VERSION ""

NS_ :

BS_:

BU_: Vector__XXX

BO_ 2449527809 SCU1_Alarm: 8 Vector__XXX
SG_ SCU1_af_CellVoltageMax : 0|1@1+ (1,0) [0|1] "" Vector__XXX
SG_ SCU1_af_CellVoltageMin : 1|1@1+ (1,0) [0|1] "" Vector__XXX
SG_ SCU1_af_SysVoltageMax : 2|1@1+ (1,0) [0|1] "" Vector__XXX
SG_ SCU1_af_SysVoltageMin : 3|1@1+ (1,0) [0|1] "" Vector__XXX
SG_ SCU1_af_SysVoltageSum : 4|1@1+ (1,0) [0|1] "" Vector__XXX
SG_ SCU1_af_ModVoltageSum : 5|1@1+ (1,0) [0|1] "" Vector__XXX
SG_ SCU1_af_ModVoltageRefMax : 6|1@1+ (1,0) [0|1] "" Vector__XXX
SG_ SCU1_af_Mod_Voltage_Ref_Min : 7|1@1+ (1,0) [0|1] "" Vector__XXX
SG_ SCU1_af_IsoFaultBattNeg : 8|1@1+ (1,0) [0|1] "" Vector__XXX
SG_ SCU1_af_IsoFaultBattPos : 9|1@1+ (1,0) [0|1] "" Vector__XXX
SG_ SCU1_af_ContactorNegStuck : 10|1@1+ (1,0) [0|1] "" Vector__XXX
SG_ SCU1_af_ContactorPosStuck : 11|1@1+ (1,0) [0|1] "" Vector__XXX
SG_ SCU1_af_LVSupplyMax : 12|1@1+ (1,0) [0|1] "" Vector__XXX
SG_ SCU1_af_LVSupplyMin : 13|1@1+ (1,0) [0|1] "" Vector__XXX
SG_ SCU1_af_TerminalTempMax : 14|1@1+ (1,0) [0|1] "" Vector__XXX
SG_ SCU1_af_TerminalTempMin : 15|1@1+ (1,0) [0|1] "" Vector__XXX
SG_ SCU1_af_CellTempChargMax : 16|1@1+ (1,0) [0|1] "" Vector__XXX
SG_ SCU1_af_CellTempChargMin : 17|1@1+ (1,0) [0|1] "" Vector__XXX
SG_ SCU1_af_CellTempDischMax : 18|1@1+ (1,0) [0|1] "" Vector__XXX
SG_ SCU1_af_CellTempDischMin : 19|1@1+ (1,0) [0|1] "" Vector__XXX
SG_ SCU1_af_SysCurCha : 20|1@1+ (1,0) [0|1] "" Vector__XXX
SG_ SCU1_af_SysCurDis : 21|1@1+ (1,0) [0|1] "" Vector__XXX
SG_ SCU1_af_HVCurrLoopMax : 22|1@1+ (1,0) [0|1] "" Vector__XXX
SG_ SCU1_af_HVCurrLoopMin : 23|1@1+ (1,0) [0|1] "" Vector__XXX
SG_ SCU1_af_eStopCurrLoopMax : 24|1@1+ (1,0) [0|1] "" Vector__XXX
SG_ SCU1_af_eStopCurrLoopMin : 25|1@1+ (1,0) [0|1] "" Vector__XXX
SG_ SCU1_af_SysCurLimitCha : 26|1@1+ (1,0) [0|1] "" Vector__XXX
SG_ SCU1_af_SysCurLimitDis : 27|1@1+ (1,0) [0|1] "" Vector__XXX
SG_ SCU1_af_SysPrechargeFailed : 28|1@1+ (1,0) [0|1] "" Vector__XXX
SG_ SCU1_af_BMMBattCom : 29|1@1+ (1,0) [0|1] "" Vector__XXX
SG_ SCU1_af_SysInitTimeout : 30|1@1+ (1,0) [0|1] "" Vector__XXX
SG_ SCU1_af_SCUConfig : 31|1@1+ (1,0) [0|1] "" Vector__XXX
SG_ SCU1_af_DeepDischProt : 32|1@1+ (1,0) [0|1] "" Vector__XXX
SG_ SCU1_af_WDReset : 33|1@1+ (1,0) [0|1] "" Vector__XXX
SG_ SCU1_af_ExtCommunicationTout : 34|1@1+ (1,0) [0|1] "" Vector__XXX
SG_ SCU1_af_NoAfterrunTest : 35|1@1+ (1,0) [0|1] "" Vector__XXX
SG_ SCU1_af_CellVoltUnbalance : 36|1@1+ (1,0) [0|1] "" Vector__XXX
SG_ SCU1_af_CellTempUnbalance : 37|1@1+ (1,0) [0|1] "" Vector__XXX
SG_ SCU1_af_TerminalTempUnbalance : 38|1@1+ (1,0) [0|1] "" Vector__XXX
SG_ SCU1_af_LTCError : 39|1@1+ (1,0) [0|1] "" Vector__XXX
SG_ SCU1_af_AfterrunTest : 40|1@1+ (1,0) [0|1] "" Vector__XXX
SG_ SCU1_af_CrossCheck : 41|1@1+ (1,0) [0|1] "" Vector__XXX
SG_ SCU1_af_StuckAtTemp : 42|1@1+ (1,0) [0|1] "" Vector__XXX
SG_ SCU1_af_StuckAtVolt : 43|1@1+ (1,0) [0|1] "" Vector__XXX
SG_ SCU1_af_ProgProcess : 44|1@1+ (1,0) [0|1] "" Vector__XXX
SG_ SCU1_af_RAM : 45|1@1+ (1,0) [0|1] "" Vector__XXX
SG_ SCU1_af_ROM : 46|1@1+ (1,0) [0|1] "" Vector__XXX
SG_ SCU1_af_FlashEEPROM : 47|1@1+ (1,0) [0|1] "" Vector__XXX
SG_ SCU1_af_InvalidData : 48|1@1+ (1,0) [0|1] "" Vector__XXX
SG_ SCU1_af_ContactorWrongState : 49|1@1+ (1,0) [0|1] "" Vector__XXX
SG_ SCU1_af_CurrSens : 50|1@1+ (1,0) [0|1] "" Vector__XXX
SG_ SCU1_af_ContDam : 51|1@1+ (1,0) [0|1] "" Vector__XXX
SG_ SCU1_af_RefVoltErrorMax : 52|1@1+ (1,0) [0|1] "" Vector__XXX
SG_ SCU1_af_RefVoltErrorMin : 53|1@1+ (1,0) [0|1] "" Vector__XXX
SG_ SCU1_af_KL30SafeMax : 54|1@1+ (1,0) [0|1] "" Vector__XXX
SG_ SCU1_af_KL30SafeMin : 55|1@1+ (1,0) [0|1] "" Vector__XXX
SG_ SCU1_af_CPUSupplyWarning : 56|1@1+ (1,0) [0|1] "" Vector__XXX
SG_ SCU1_af_PowerProtectionWarning : 57|1@1+ (1,0) [0|1] "" Vector__XXX
SG_ SCU1_af_KL30SafeOff : 58|1@1+ (1,0) [0|1] "" Vector__XXX
SG_ SCU1_af_Dew_Sensor : 59|1@1+ (1,0) [0|1] "" Vector__XXX
SG_ SCU1_af_ContactorDropOut : 60|1@1+ (1,0) [0|1] "" Vector__XXX
SG_ SCU1_af_BoardTemp : 61|1@1+ (1,0) [0|1] "" Vector__XXX
SG_ SCU1_af_SCUError : 63|1@1+ (1,0) [0|1] "" Vector__XXX

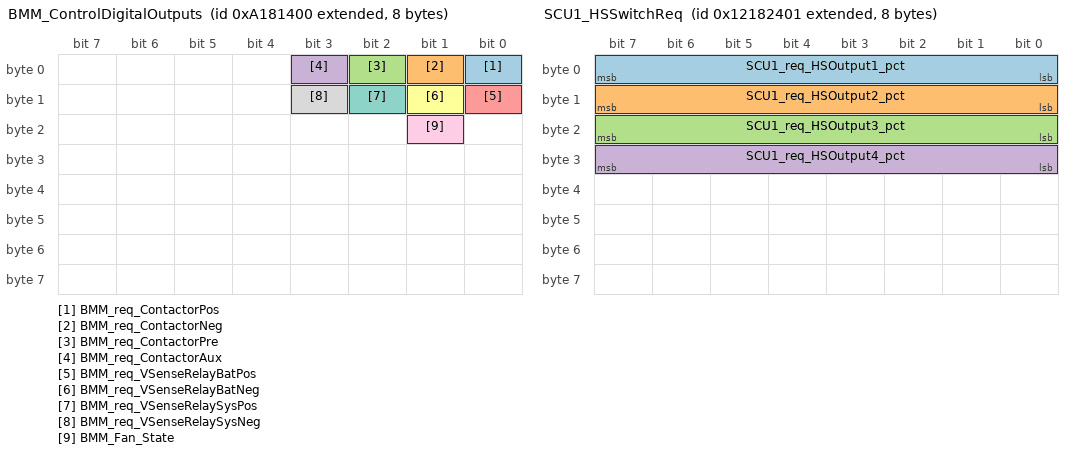
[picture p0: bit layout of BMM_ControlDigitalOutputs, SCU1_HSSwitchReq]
BO_ 2316833792 BMM_ControlDigitalOutputs: 8 Vector__XXX
SG_ BMM_req_ContactorPos : 0|1@1+ (1,0) [0|1] "" Vector__XXX
SG_ BMM_req_ContactorNeg : 1|1@1+ (1,0) [0|1] "" Vector__XXX
SG_ BMM_req_ContactorPre : 2|1@1+ (1,0) [0|1] "" Vector__XXX
SG_ BMM_req_ContactorAux : 3|1@1+ (1,0) [0|1] "" Vector__XXX
SG_ BMM_req_VSenseRelayBatPos : 8|1@1+ (1,0) [0|1] "" Vector__XXX
SG_ BMM_req_VSenseRelayBatNeg : 9|1@1+ (1,0) [0|1] "" Vector__XXX
SG_ BMM_req_VSenseRelaySysPos : 10|1@1+ (1,0) [0|1] "" Vector__XXX
SG_ BMM_req_VSenseRelaySysNeg : 11|1@1+ (1,0) [0|1] "" Vector__XXX
SG_ BMM_Fan_State : 17|1@1+ (1,0) [0|1] "" Vector__XXX

BO_ 2651595777 SCU1_CtrlDigitalOutputs_diag: 8 Vector__XXX
SG_ SCU1_req_ContactorPosDiag : 0|1@1+ (1,0) [0|1] "" Vector__XXX
SG_ SCU1_req_ContactorNegDiag : 1|1@1+ (1,0) [0|1] "" Vector__XXX
SG_ SCU1_req_ContactorPreDiag : 2|1@1+ (1,0) [0|1] "" Vector__XXX
SG_ SCU1_req_ContactorAuxDiag : 3|1@1+ (1,0) [0|1] "" Vector__XXX
SG_ SCU1_req_VSenseRelayBatPosDiag : 8|1@1+ (1,0) [0|1] "" Vector__XXX
SG_ SCU1_req_VSenseRelayBatNegDiag : 9|1@1+ (1,0) [0|1] "" Vector__XXX
SG_ SCU1_req_VSenseRelaySysPosDiag : 10|1@1+ (1,0) [0|1] "" Vector__XXX
SG_ SCU1_req_VSenseRelaySysNegDiag : 11|1@1+ (1,0) [0|1] "" Vector__XXX
SG_ SCU1_req_ShutdownDiag : 16|1@1+ (1,0) [0|1] "" Vector__XXX
SG_ SCU1_req_CANGatewayDiag : 17|1@1+ (1,0) [0|1] "" Vector__XXX
SG_ SCU1_req_eStopBrakeOutDiag : 18|1@1+ (1,0) [0|1] "" Vector__XXX
SG_ SCU1_req_InterlockSourceDiag : 19|1@1+ (1,0) [0|1] "" Vector__XXX
SG_ SCU1_req_WdgTrigOffDiag : 20|1@1+ (1,0) [0|1] "" Vector__XXX
SG_ SCU1_req_SafetyEnable1Diag : 21|1@1+ (1,0) [0|1] "" Vector__XXX
SG_ SCU1_req_SafetyEnable2Diag : 22|1@1+ (1,0) [0|1] "" Vector__XXX
SG_ SCU1_req_BMSPowerDiag : 23|1@1+ (1,0) [0|1] "" Vector__XXX
SG_ SCU1_req_SystemResetDiag : 24|1@1+ (1,0) [0|1] "" Vector__XXX
SG_ SCU1_req_LEDDiag : 25|1@1+ (1,0) [0|1] "" Vector__XXX
SG_ SCU1_req_WdgTrigFastDiag : 26|1@1+ (1,0) [0|1] "" Vector__XXX
SG_ SCU1_req_WdgAlarmResetDiag : 27|1@1+ (1,0) [0|1] "" Vector__XXX

BO_ 2451055617 SCU1_HSSwitchReq: 8 Vector__XXX
SG_ SCU1_req_HSOutput1_pct : 0|8@1+ (1,0) [0|255] "%" Vector__XXX
SG_ SCU1_req_HSOutput2_pct : 8|8@1+ (1,0) [0|255] "%" Vector__XXX
SG_ SCU1_req_HSOutput3_pct : 16|8@1+ (1,0) [0|255] "%" Vector__XXX
SG_ SCU1_req_HSOutput4_pct : 24|8@1+ (1,0) [0|255] "%" Vector__XXX

BO_ 2449540097 SCU1_SWConfigInfo: 8 Vector__XXX
SG_ SCU1_inf_NumOfModule : 0|8@1+ (1,0) [0|255] "" Vector__XXX
SG_ SCU1_inf_NumOfCell : 8|8@1+ (1,0) [0|255] "" Vector__XXX
SG_ SCU1_inf_Checksum : 32|32@1+ (1,0) [0|4294967295] "" Vector__XXX

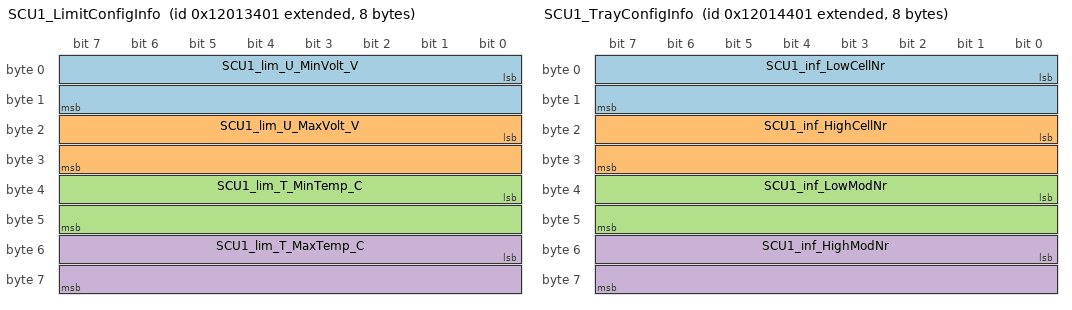
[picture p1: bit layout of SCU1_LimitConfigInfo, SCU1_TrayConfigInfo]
BO_ 2449552385 SCU1_LimitConfigInfo: 8 Vector__XXX
SG_ SCU1_lim_U_MinVolt_V : 0|16@1+ (0.001,0) [0|65.535] "V" Vector__XXX
SG_ SCU1_lim_U_MaxVolt_V : 16|16@1+ (0.001,0) [0|65.535] "V" Vector__XXX
SG_ SCU1_lim_T_MinTemp_C : 32|16@1- (0.1,0) [-3276.8|3276.7] "T" Vector__XXX
SG_ SCU1_lim_T_MaxTemp_C : 48|16@1- (0.1,0) [-3276.8|3276.7] "T" Vector__XXX

BO_ 2449556481 SCU1_TrayConfigInfo: 8 Vector__XXX
SG_ SCU1_inf_LowCellNr : 0|16@1+ (1,0) [0|65535] "" Vector__XXX
SG_ SCU1_inf_HighCellNr : 16|16@1+ (1,0) [0|65535] "" Vector__XXX
SG_ SCU1_inf_LowModNr : 32|16@1+ (1,0) [0|65535] "" Vector__XXX
SG_ SCU1_inf_HighModNr : 48|16@1+ (1,0) [0|65535] "" Vector__XXX

BO_ 2348811265 SCU1_GatewayTest: 8 Vector__XXX

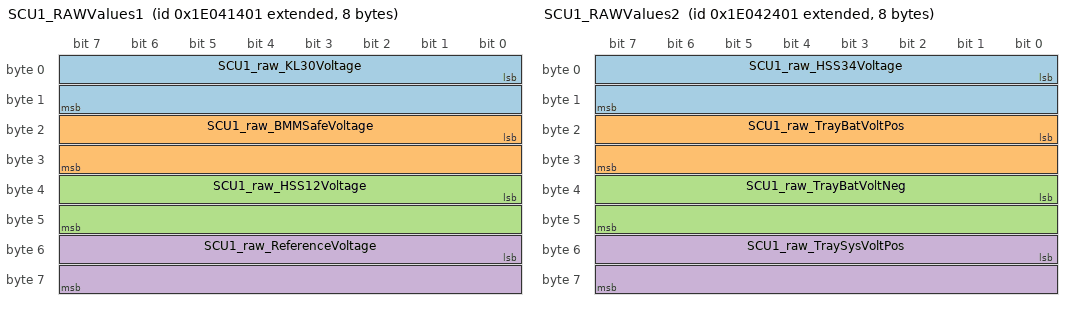
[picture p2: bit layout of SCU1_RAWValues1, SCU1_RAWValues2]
BO_ 2651067393 SCU1_RAWValues1: 8 Vector__XXX
SG_ SCU1_raw_KL30Voltage : 0|16@1+ (1,0) [0|65535] "digit" Vector__XXX
SG_ SCU1_raw_BMMSafeVoltage : 16|16@1+ (1,0) [0|65535] "digit" Vector__XXX
SG_ SCU1_raw_HSS12Voltage : 32|16@1+ (1,0) [0|65535] "digit" Vector__XXX
SG_ SCU1_raw_ReferenceVoltage : 48|16@1+ (1,0) [0|65535] "digit" Vector__XXX

BO_ 2651071489 SCU1_RAWValues2: 8 Vector__XXX
SG_ SCU1_raw_HSS34Voltage : 0|16@1+ (1,0) [0|65535] "digit" Vector__XXX
SG_ SCU1_raw_TrayBatVoltPos : 16|16@1+ (1,0) [0|65535] "digit" Vector__XXX
SG_ SCU1_raw_TrayBatVoltNeg : 32|16@1+ (1,0) [0|65535] "digit" Vector__XXX
SG_ SCU1_raw_TraySysVoltPos : 48|16@1+ (1,0) [0|65535] "digit" Vector__XXX

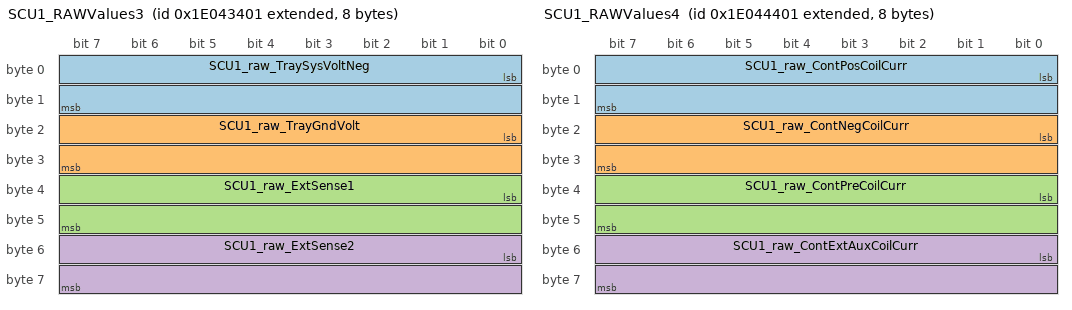
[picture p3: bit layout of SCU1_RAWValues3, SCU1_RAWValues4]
BO_ 2651075585 SCU1_RAWValues3: 8 Vector__XXX
SG_ SCU1_raw_TraySysVoltNeg : 0|16@1+ (1,0) [0|65535] "digit" Vector__XXX
SG_ SCU1_raw_TrayGndVolt : 16|16@1+ (1,0) [0|65535] "digit" Vector__XXX
SG_ SCU1_raw_ExtSense1 : 32|16@1+ (1,0) [0|65535] "digit" Vector__XXX
SG_ SCU1_raw_ExtSense2 : 48|16@1+ (1,0) [0|65535] "digit" Vector__XXX

BO_ 2651079681 SCU1_RAWValues4: 8 Vector__XXX
SG_ SCU1_raw_ContPosCoilCurr : 0|16@1+ (1,0) [0|65535] "digit" Vector__XXX
SG_ SCU1_raw_ContNegCoilCurr : 16|16@1+ (1,0) [0|65535] "digit" Vector__XXX
SG_ SCU1_raw_ContPreCoilCurr : 32|16@1+ (1,0) [0|65535] "digit" Vector__XXX
SG_ SCU1_raw_ContExtAuxCoilCurr : 48|16@1+ (1,0) [0|65535] "digit" Vector__XXX

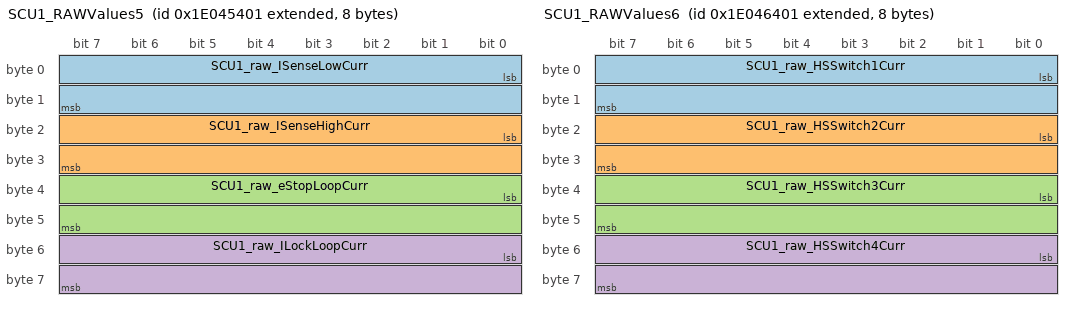
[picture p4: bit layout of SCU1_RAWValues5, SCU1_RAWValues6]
BO_ 2651083777 SCU1_RAWValues5: 8 Vector__XXX
SG_ SCU1_raw_ISenseLowCurr : 0|16@1+ (1,0) [0|65535] "digit" Vector__XXX
SG_ SCU1_raw_ISenseHighCurr : 16|16@1+ (1,0) [0|65535] "digit" Vector__XXX
SG_ SCU1_raw_eStopLoopCurr : 32|16@1+ (1,0) [0|65535] "digit" Vector__XXX
SG_ SCU1_raw_ILockLoopCurr : 48|16@1+ (1,0) [0|65535] "digit" Vector__XXX

BO_ 2651087873 SCU1_RAWValues6: 8 Vector__XXX
SG_ SCU1_raw_HSSwitch1Curr : 0|16@1+ (1,0) [0|65535] "digit" Vector__XXX
SG_ SCU1_raw_HSSwitch2Curr : 16|16@1+ (1,0) [0|65535] "digit" Vector__XXX
SG_ SCU1_raw_HSSwitch3Curr : 32|16@1+ (1,0) [0|65535] "digit" Vector__XXX
SG_ SCU1_raw_HSSwitch4Curr : 48|16@1+ (1,0) [0|65535] "digit" Vector__XXX

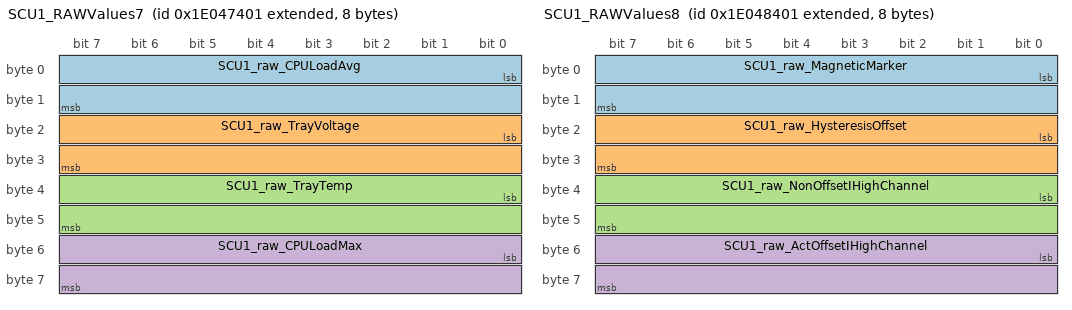
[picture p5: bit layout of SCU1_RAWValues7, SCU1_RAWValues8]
BO_ 2651091969 SCU1_RAWValues7: 8 Vector__XXX
SG_ SCU1_raw_CPULoadAvg : 0|16@1+ (0.1,0) [0|6553.5] "%" Vector__XXX
SG_ SCU1_raw_TrayVoltage : 16|16@1+ (1,0) [0|65535] "digit" Vector__XXX
SG_ SCU1_raw_TrayTemp : 32|16@1+ (1,0) [0|65535] "digit" Vector__XXX
SG_ SCU1_raw_CPULoadMax : 48|16@1+ (0.1,0) [0|6553.5] "%" Vector__XXX

BO_ 2651096065 SCU1_RAWValues8: 8 Vector__XXX
SG_ SCU1_raw_MagneticMarker : 0|16@1+ (1,0) [0|65535] "" Vector__XXX
SG_ SCU1_raw_HysteresisOffset : 16|16@1+ (1,0) [0|65535] "" Vector__XXX
SG_ SCU1_raw_NonOffsetIHighChannel : 32|16@1+ (1,0) [0|65535] "" Vector__XXX
SG_ SCU1_raw_ActOffsetIHighChannel : 48|16@1+ (1,0) [0|65535] "" Vector__XXX

BO_ 2651100161 SCU1_RAWValues9: 8 Vector__XXX
SG_ SCU1_raw_DIO_P02_00_In : 0|1@1+ (1,0) [0|1] "" Vector__XXX
SG_ SCU1_raw_DIO_P02_01_In : 1|1@1+ (1,0) [0|1] "" Vector__XXX
SG_ SCU1_raw_DIO_P02_02_In : 2|1@1+ (1,0) [0|1] "" Vector__XXX
SG_ SCU1_raw_DIO_P02_05_Out : 3|1@1+ (1,0) [0|1] "" Vector__XXX
SG_ SCU1_raw_DIO_P02_06_In : 4|1@1+ (1,0) [0|1] "" Vector__XXX
SG_ SCU1_raw_DIO_P02_07_In : 5|1@1+ (1,0) [0|1] "" Vector__XXX
SG_ SCU1_raw_DIO_P02_12_Out : 6|1@1+ (1,0) [0|1] "" Vector__XXX
SG_ SCU1_raw_DIO_P03_03_Out : 7|1@1+ (1,0) [0|1] "" Vector__XXX
SG_ SCU1_raw_DIO_P03_04_Out : 8|1@1+ (1,0) [0|1] "" Vector__XXX
SG_ SCU1_raw_DIO_P04_04_Out : 9|1@1+ (1,0) [0|1] "" Vector__XXX
SG_ SCU1_raw_DIO_P04_05_Out : 10|1@1+ (1,0) [0|1] "" Vector__XXX
SG_ SCU1_raw_DIO_P04_06_Out : 11|1@1+ (1,0) [0|1] "" Vector__XXX
SG_ SCU1_raw_DIO_P04_07_Out : 12|1@1+ (1,0) [0|1] "" Vector__XXX
SG_ SCU1_raw_DIO_P06_02_Out : 13|1@1+ (1,0) [0|1] "" Vector__XXX
SG_ SCU1_raw_DIO_P06_03_Out : 14|1@1+ (1,0) [0|1] "" Vector__XXX
SG_ SCU1_raw_DIO_P07_01_Out : 15|1@1+ (1,0) [0|1] "" Vector__XXX
SG_ SCU1_raw_DIO_P07_02_Out : 16|1@1+ (1,0) [0|1] "" Vector__XXX
SG_ SCU1_raw_DIO_P08_03_Out : 17|1@1+ (1,0) [0|1] "" Vector__XXX
SG_ SCU1_raw_DIO_P08_04_Out : 18|1@1+ (1,0) [0|1] "" Vector__XXX
SG_ SCU1_raw_DIO_P08_05_Out : 19|1@1+ (1,0) [0|1] "" Vector__XXX
SG_ SCU1_raw_DIO_P08_06_Out : 20|1@1+ (1,0) [0|1] "" Vector__XXX
SG_ SCU1_raw_DIO_P09_00_BiIO : 21|1@1+ (1,0) [0|1] "" Vector__XXX
SG_ SCU1_raw_DIO_P09_01_Out : 22|1@1+ (1,0) [0|1] "" Vector__XXX
SG_ SCU1_raw_DIO_P09_02_Out : 23|1@1+ (1,0) [0|1] "" Vector__XXX
SG_ SCU1_raw_DIO_P09_03_Out : 24|1@1+ (1,0) [0|1] "" Vector__XXX
SG_ SCU1_raw_DIO_P09_04_Out : 25|1@1+ (1,0) [0|1] "" Vector__XXX
SG_ SCU1_raw_DIO_P09_05_BiIO : 26|1@1+ (1,0) [0|1] "" Vector__XXX
SG_ SCU1_raw_DIO_P09_06_BiIO : 27|1@1+ (1,0) [0|1] "" Vector__XXX
SG_ SCU1_raw_DIO_P09_07_BiIO : 28|1@1+ (1,0) [0|1] "" Vector__XXX
SG_ SCU1_raw_DIO_P10_08_BiIO : 29|1@1+ (1,0) [0|1] "" Vector__XXX
SG_ SCU1_raw_DIO_P10_09_BiIO : 30|1@1+ (1,0) [0|1] "" Vector__XXX
SG_ SCU1_raw_DIO_P10_10_Out : 31|1@1+ (1,0) [0|1] "" Vector__XXX
SG_ SCU1_raw_DIO_P10_11_Out : 32|1@1+ (1,0) [0|1] "" Vector__XXX
SG_ SCU1_raw_DIO_P10_12_Out : 33|1@1+ (1,0) [0|1] "" Vector__XXX
SG_ SCU1_raw_DIO_P11_02_Out : 34|1@1+ (1,0) [0|1] "" Vector__XXX
SG_ SCU1_raw_DIO_P11_03_Out : 35|1@1+ (1,0) [0|1] "" Vector__XXX
SG_ SCU1_raw_DIO_P11_04_Out : 36|1@1+ (1,0) [0|1] "" Vector__XXX
SG_ SCU1_raw_DIO_P11_05_Out : 37|1@1+ (1,0) [0|1] "" Vector__XXX
SG_ SCU1_raw_DIO_ESR0_In : 38|1@1+ (1,0) [0|1] "" Vector__XXX
SG_ SCU1_raw_DIO_ESR1_In : 39|1@1+ (1,0) [0|1] "" Vector__XXX
SG_ SCU1_raw_DIO_ESR2_In : 40|1@1+ (1,0) [0|1] "" Vector__XXX

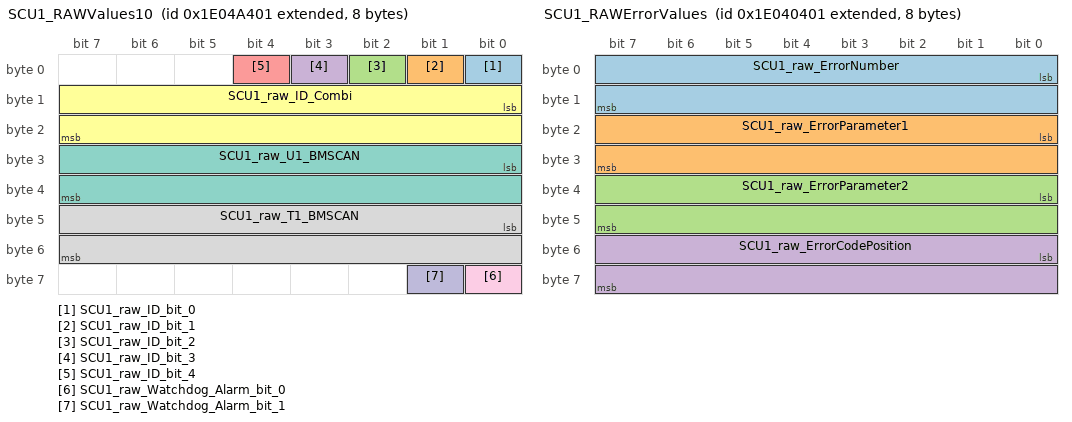
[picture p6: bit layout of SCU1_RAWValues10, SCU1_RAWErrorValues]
BO_ 2651104257 SCU1_RAWValues10: 8 Vector__XXX
SG_ SCU1_raw_ID_bit_0 : 0|1@1+ (1,0) [0|1] "" Vector__XXX
SG_ SCU1_raw_ID_bit_1 : 1|1@1+ (1,0) [0|1] "" Vector__XXX
SG_ SCU1_raw_ID_bit_2 : 2|1@1+ (1,0) [0|1] "" Vector__XXX
SG_ SCU1_raw_ID_bit_3 : 3|1@1+ (1,0) [0|1] "" Vector__XXX
SG_ SCU1_raw_ID_bit_4 : 4|1@1+ (1,0) [0|1] "" Vector__XXX
SG_ SCU1_raw_ID_Combi : 8|16@1+ (1,0) [0|65535] "" Vector__XXX
SG_ SCU1_raw_U1_BMSCAN : 24|16@1- (1,0) [-32768|32767] "" Vector__XXX
SG_ SCU1_raw_T1_BMSCAN : 40|16@1- (1,0) [-32768|32767] "" Vector__XXX
SG_ SCU1_raw_Watchdog_Alarm_bit_0 : 56|1@1+ (1,0) [0|1] "" Vector__XXX
SG_ SCU1_raw_Watchdog_Alarm_bit_1 : 57|1@1+ (1,0) [0|1] "" Vector__XXX

BO_ 2651063297 SCU1_RAWErrorValues: 8 Vector__XXX
SG_ SCU1_raw_ErrorNumber : 0|16@1+ (1,0) [0|65535] "" Vector__XXX
SG_ SCU1_raw_ErrorParameter1 : 16|16@1+ (1,0) [0|65535] "" Vector__XXX
SG_ SCU1_raw_ErrorParameter2 : 32|16@1+ (1,0) [0|65535] "" Vector__XXX
SG_ SCU1_raw_ErrorCodePosition : 48|16@1+ (1,0) [0|65535] "" Vector__XXX

BO_ 2651587585 SCU1_DiagActivation: 8 Vector__XXX
SG_ SCU1_val_DiagActivationID : 0|64@1+ (1,0) [0|1.84467440737096E019] "" Vector__XXX

BO_ 2181563392 BMM_SCUSyncMsg: 0 Vector__XXX

BO_ 2315342849 SCU1_ContactorDmg: 8 Vector__XXX
SG_ SCU1_ctr_DamageTotal : 0|32@1+ (1,0) [0|4294967295] "" Vector__XXX
SG_ SCU1_ctr_ContOperational_s : 32|32@1+ (1,0) [0|4294967295] "" Vector__XXX

BO_ 2651591681 SCU1_SetSystemValues: 8 Vector__XXX
SG_ SCU1_val_DamageResetMagic : 0|24@1+ (1,0) [0|16777215] "" Vector__XXX
SG_ SCU1_val_ResetType : 24|8@1+ (1,0) [0|255] "" Vector__XXX
SG_ SCU1_conf_ResetValue : 32|32@1+ (1,0) [0|4294967295] "" Vector__XXX
SG_ SCU1_vrr_Day : 48|8@1+ (1,0) [0|255] "" Vector__XXX
SG_ SCU1_vrr_Month : 40|8@1+ (1,0) [0|255] "" Vector__XXX
SG_ SCU1_vrr_2kYear : 32|8@1+ (1,0) [0|255] "" Vector__XXX
SG_ SCU1_vrr_Hour : 48|8@1+ (1,0) [0|255] "" Vector__XXX
SG_ SCU1_vrr_Minute : 40|8@1+ (1,0) [0|255] "" Vector__XXX
SG_ SCU1_vrr_Second : 32|8@1+ (1,0) [0|255] "" Vector__XXX

BO_ 2449564673 SCU1_OperationTimeCounter: 8 Vector__XXX
SG_ SCU1_ctr_t_AliveTime_s : 0|32@1+ (1,0) [0|4294967295] "s" Vector__XXX
SG_ SCU1_ctr_t_OperationTime_s : 32|32@1+ (1,0) [0|4294967295] "s" Vector__XXX

BO_ 2449568769 SCU1_AmpereHourCounter: 8 Vector__XXX
SG_ SCU1_ctr_Q_AmpereHourChg_Ah : 0|32@1+ (0.01,0) [0|42949672.95] "Ah" Vector__XXX
SG_ SCU1_ctr_Q_AmpereHourDisch_Ah : 32|32@1+ (0.01,0) [0|42949672.95] "Ah" Vector__XXX

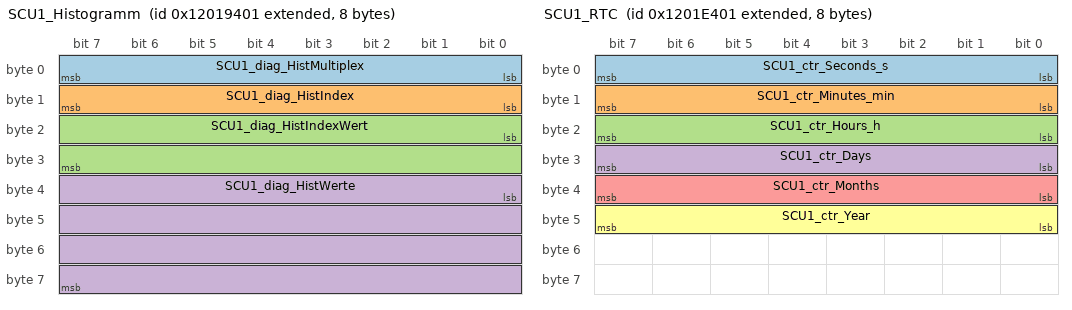
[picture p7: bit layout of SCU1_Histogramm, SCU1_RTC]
BO_ 2449576961 SCU1_Histogramm: 8 Vector__XXX
SG_ SCU1_diag_HistMultiplex : 0|8@1+ (1,0) [0|255] "" Vector__XXX
SG_ SCU1_diag_HistIndex : 8|8@1+ (1,0) [0|255] "" Vector__XXX
SG_ SCU1_diag_HistIndexWert : 16|16@1- (1,0) [-32768|32767] "" Vector__XXX
SG_ SCU1_diag_HistWerte : 32|32@1+ (1,0) [0|4294967295] "" Vector__XXX

BO_ 2449597441 SCU1_RTC: 8 Vector__XXX
SG_ SCU1_ctr_Seconds_s : 0|8@1+ (1,0) [0|255] "" Vector__XXX
SG_ SCU1_ctr_Minutes_min : 8|8@1+ (1,0) [0|255] "" Vector__XXX
SG_ SCU1_ctr_Hours_h : 16|8@1+ (1,0) [0|255] "" Vector__XXX
SG_ SCU1_ctr_Days : 24|8@1+ (1,0) [0|255] "" Vector__XXX
SG_ SCU1_ctr_Months : 32|8@1+ (1,0) [0|255] "" Vector__XXX
SG_ SCU1_ctr_Year : 40|8@1+ (1,0) [0|255] "" Vector__XXX

BO_ 2449536001 SCU1_LoopCurrents: 8 Vector__XXX
SG_ SCU1_act_I_HVIL_mA : 0|16@1- (0.1,0) [-3276.8|3276.7] "mA" Vector__XXX
SG_ SCU1_act_I_eStop_mA : 16|16@1- (0.1,0) [-3276.8|3276.7] "mA" Vector__XXX
SG_ SCU1_act_I_CurrentSensTot_A : 32|16@1- (0.1,0) [-3276.8|3276.7] "A" Vector__XXX

BO_ 2449548289 SCU1_SysInfo: 8 Vector__XXX
SG_ SCU1_SysInfo_Mux M : 0|8@1+ (1,0) [0|0] "" Vector__XXX
SG_ SCU1_inf_CPUBoardId m0 : 8|56@1+ (1,0) [0|7.20575940379279E016] "" Vector__XXX
SG_ SCU1_inf_HVBoardId m1 : 8|56@1+ (1,0) [0|7.20575940379279E016] "" Vector__XXX
SG_ SCU1_inf_BBoardId m2 : 8|56@1+ (1,0) [0|7.20575940379279E016] "" Vector__XXX
SG_ SCU1_inf_MRCCBBoardId m3 : 8|56@1+ (1,0) [0|7.20575940379279E016] "" Vector__XXX
SG_ SCU1_inf_HwRevMinor m4 : 8|8@1+ (1,0) [0|255] "" Vector__XXX
SG_ SCU1_inf_HwRevMajor m4 : 16|8@1+ (1,0) [0|255] "" Vector__XXX
SG_ SCU1_inf_ChipRevSubstep m5 : 8|4@1+ (1,0) [0|15] "" Vector__XXX
SG_ SCU1_inf_ChipRevStep m5 : 12|2@1+ (1,0) [0|3] "" Vector__XXX
SG_ SCU1_inf_ChipFam m5 : 14|2@1+ (1,0) [0|3] "" Vector__XXX
SG_ SCU1_inf_ChipId m5 : 16|8@1+ (1,0) [0|255] "" Vector__XXX
SG_ SCU1_inf_ChipEmuExt m5 : 24|1@1+ (1,0) [0|1] "" Vector__XXX
SG_ SCU1_inf_ChipMicroCodeVer m5 : 25|7@1+ (1,0) [0|127] "" Vector__XXX
SG_ SCU1_inf_ChipFlashSize m5 : 32|4@1+ (1,0) [0|15] "" Vector__XXX
SG_ SCU1_inf_ChipSpeedGrade m5 : 36|2@1+ (1,0) [0|3] "" Vector__XXX
SG_ SCU1_inf_ChipSecModule m5 : 38|1@1+ (1,0) [0|1] "" Vector__XXX

BO_ 2449544193 SCU1_AkaSerialNo: 8 Vector__XXX
SG_ SCU1_AkaSerialNo_Mux M : 58|4@1+ (1,0) [0|0] "" Vector__XXX
SG_ SCU1_Aka_Year_P m0 : 51|7@1+ (1,0) [0|127] "" Vector__XXX
SG_ SCU1_Aka_Week_P m0 : 45|6@1+ (1,0) [0|63] "" Vector__XXX
SG_ SCU1_Aka_Plant m0 : 38|7@1+ (1,0) [0|127] "" Vector__XXX
SG_ SCU1_Aka_Line m0 : 31|7@1+ (1,0) [0|127] "" Vector__XXX
SG_ SCU1_Aka_Los_No_P m0 : 0|31@1+ (1,0) [0|2147483647] "" Vector__XXX
SG_ SCU1_Aka_Year_E m1 : 51|7@1+ (1,0) [0|127] "" Vector__XXX
SG_ SCU1_Aka_Week_E m1 : 45|6@1+ (1,0) [0|63] "" Vector__XXX
SG_ SCU1_Aka_Module m1 : 31|14@1+ (1,0) [0|16383] "" Vector__XXX
SG_ SCU1_Aka_Version m1 : 24|7@1+ (1,0) [0|127] "" Vector__XXX
SG_ SCU1_Aka_Supplier m1 : 14|10@1+ (1,0) [0|1023] "" Vector__XXX
SG_ SCU1_Aka_Los_No_E m1 : 0|13@1+ (1,0) [0|8191] "" Vector__XXX
SG_ SCU1_Aka_Year_S m3 : 51|7@1+ (1,0) [0|127] "" Vector__XXX
SG_ SCU1_Aka_Week_S m3 : 45|6@1+ (1,0) [0|63] "" Vector__XXX
SG_ SCU1_Aka_Major m3 : 38|7@1+ (1,0) [0|127] "" Vector__XXX
SG_ SCU1_Aka_Minor m3 : 31|7@1+ (1,0) [0|127] "" Vector__XXX
SG_ SCU1_Aka_Build_No m3 : 21|10@1+ (1,0) [0|1023] "" Vector__XXX
SG_ SCU1_Aka_BuildUserNr m3 : 14|7@1+ (1,0) [0|127] "" Vector__XXX
SG_ SCU1_Aka_SWVariant m3 : 0|14@1+ (1,0) [0|16383] "" Vector__XXX

BO_ 2650801153 SCU1_DldrAcknowledge_boot: 8 Vector__XXX
SG_ SCU1_val_SerialNr : 0|48@1+ (1,0) [0|281474976710655] "" Vector__XXX
SG_ SCU1_val_HWRev : 48|16@1+ (1,0) [0|65535] "" Vector__XXX

BO_ 2650805249 SCU1_SWVersionInfo_boot: 8 Vector__XXX
SG_ SCU1_val_SWVersionNr : 0|64@1+ (1,0) [0|1.84467440737096E019] "" Vector__XXX

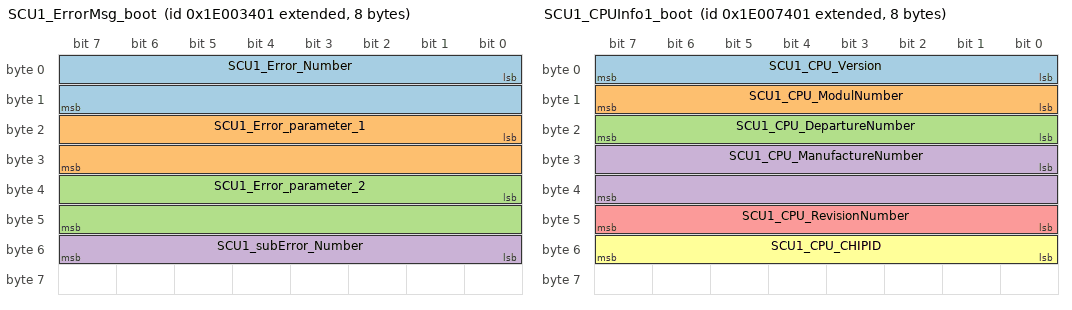
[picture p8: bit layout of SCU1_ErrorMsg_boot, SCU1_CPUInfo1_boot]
BO_ 2650813441 SCU1_ErrorMsg_boot: 8 Vector__XXX
SG_ SCU1_Error_Number : 0|16@1+ (1,0) [0|65535] "" Vector__XXX
SG_ SCU1_Error_parameter_1 : 16|16@1+ (1,0) [0|65535] "" Vector__XXX
SG_ SCU1_Error_parameter_2 : 32|16@1+ (1,0) [0|65535] "" Vector__XXX
SG_ SCU1_subError_Number : 48|8@1+ (1,0) [0|255] "" Vector__XXX

BO_ 2650817537 SCU1_ConfigVersionInfo_boot: 8 Vector__XXX
SG_ sw_version_nr : 0|64@1+ (1,0) [0|1.84467440737096E019] "" Vector__XXX

BO_ 2650825729 SCU1_SWChecksumInfo_boot: 8 Vector__XXX
SG_ SCU1_sw_checksum : 0|32@1+ (1,0) [0|4294967295] "" Vector__XXX
SG_ SCU1_config_checksum : 32|32@1+ (1,0) [0|4294967295] "" Vector__XXX

BO_ 2650829825 SCU1_CPUInfo1_boot: 8 Vector__XXX
SG_ SCU1_CPU_Version : 0|8@1+ (1,0) [0|255] "" Vector__XXX
SG_ SCU1_CPU_ModulNumber : 8|8@1+ (1,0) [0|255] "" Vector__XXX
SG_ SCU1_CPU_DepartureNumber : 16|8@1+ (1,0) [0|255] "" Vector__XXX
SG_ SCU1_CPU_ManufactureNumber : 24|16@1+ (1,0) [0|65535] "" Vector__XXX
SG_ SCU1_CPU_RevisionNumber : 40|8@1+ (1,0) [0|255] "" Vector__XXX
SG_ SCU1_CPU_CHIPID : 48|8@1+ (1,0) [0|255] "" Vector__XXX

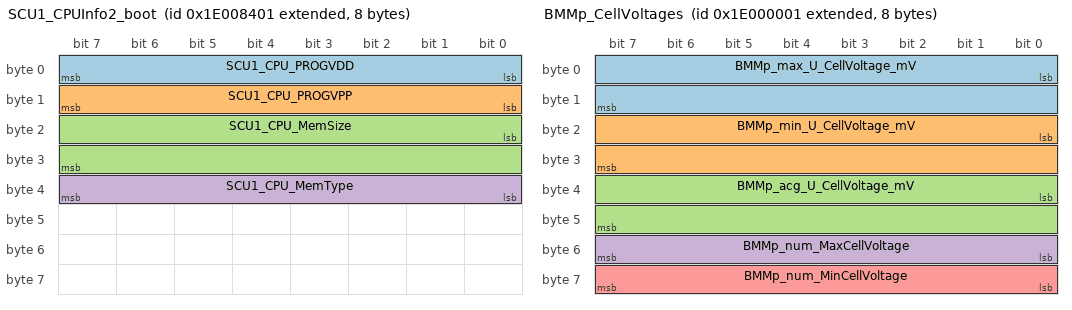
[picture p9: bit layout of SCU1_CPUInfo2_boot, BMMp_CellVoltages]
BO_ 2650833921 SCU1_CPUInfo2_boot: 8 Vector__XXX
SG_ SCU1_CPU_PROGVDD : 0|8@1+ (1,0) [0|255] "" Vector__XXX
SG_ SCU1_CPU_PROGVPP : 8|8@1+ (1,0) [0|255] "" Vector__XXX
SG_ SCU1_CPU_MemSize : 16|16@1+ (1,0) [0|65535] "" Vector__XXX
SG_ SCU1_CPU_MemType : 32|8@1+ (1,0) [0|255] "" Vector__XXX

BO_ 2650838017 SCU1_Software_Components_boot: 8 Vector__XXX
SG_ SCU1_ComponentNameActive : 0|24@1+ (1,0) [0|16777215] "char" Vector__XXX
SG_ SCU1_DownloadComponentName : 24|24@1+ (1,0) [0|16777215] "char" Vector__XXX

BO_ 2650800129 BMMp_CellVoltages: 8 Vector__XXX
SG_ BMMp_max_U_CellVoltage_mV : 0|16@1+ (1,0) [0|65535] "mV" Vector__XXX
SG_ BMMp_min_U_CellVoltage_mV : 16|16@1+ (1,0) [0|65535] "mV" Vector__XXX
SG_ BMMp_acg_U_CellVoltage_mV : 32|16@1+ (1,0) [0|65535] "mV" Vector__XXX
SG_ BMMp_num_MaxCellVoltage : 48|8@1+ (1,0) [0|255] "-" Vector__XXX
SG_ BMMp_num_MinCellVoltage : 56|8@1+ (1,0) [0|255] "-" Vector__XXX

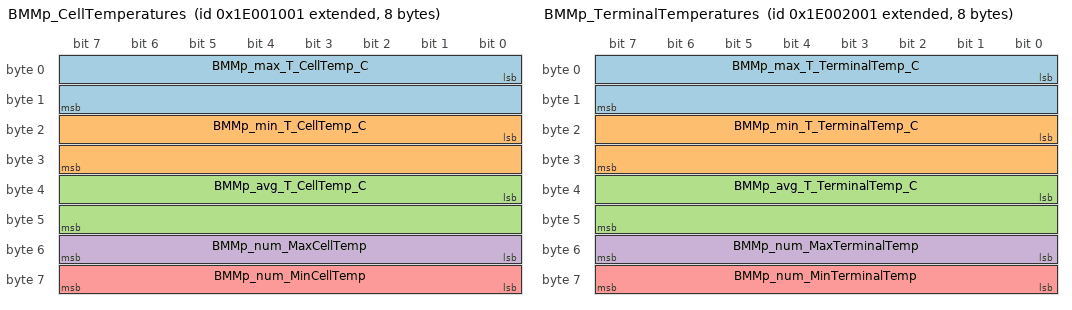
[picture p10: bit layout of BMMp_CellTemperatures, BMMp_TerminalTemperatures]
BO_ 2650804225 BMMp_CellTemperatures: 8 Vector__XXX
SG_ BMMp_max_T_CellTemp_C : 0|16@1- (0.1,0) [-3276.8|3276.7] "°C" Vector__XXX
SG_ BMMp_min_T_CellTemp_C : 16|16@1- (0.1,0) [-3276.8|3276.7] "°C" Vector__XXX
SG_ BMMp_avg_T_CellTemp_C : 32|16@1- (0.1,0) [-3276.8|3276.7] "°C" Vector__XXX
SG_ BMMp_num_MaxCellTemp : 48|8@1+ (1,0) [0|255] "-" Vector__XXX
SG_ BMMp_num_MinCellTemp : 56|8@1+ (1,0) [0|255] "-" Vector__XXX

BO_ 2650808321 BMMp_TerminalTemperatures: 8 Vector__XXX
SG_ BMMp_max_T_TerminalTemp_C : 0|16@1- (0.1,0) [-3276.8|3276.7] "°C" Vector__XXX
SG_ BMMp_min_T_TerminalTemp_C : 16|16@1- (0.1,0) [-3276.8|3276.7] "°C" Vector__XXX
SG_ BMMp_avg_T_TerminalTemp_C : 32|16@1- (0.1,0) [-3276.8|3276.7] "°C" Vector__XXX
SG_ BMMp_num_MaxTerminalTemp : 48|8@1+ (1,0) [0|255] "-" Vector__XXX
SG_ BMMp_num_MinTerminalTemp : 56|8@1+ (1,0) [0|255] "-" Vector__XXX

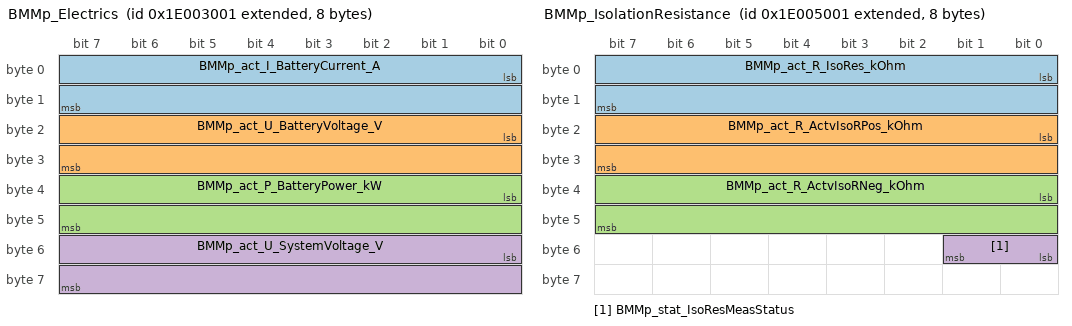
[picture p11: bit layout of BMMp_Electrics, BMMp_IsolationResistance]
BO_ 2650812417 BMMp_Electrics: 8 Vector__XXX
SG_ BMMp_act_I_BatteryCurrent_A : 0|16@1- (0.1,0) [-3276.8|3276.7] "A" Vector__XXX
SG_ BMMp_act_U_BatteryVoltage_V : 16|16@1- (0.1,0) [-3276.8|3276.7] "V" Vector__XXX
SG_ BMMp_act_P_BatteryPower_kW : 32|16@1- (0.1,0) [-3276.8|3276.7] "kW" Vector__XXX
SG_ BMMp_act_U_SystemVoltage_V : 48|16@1- (0.1,0) [-3276.8|3276.7] "V" Vector__XXX

BO_ 2650816513 BMMp_State: 8 Vector__XXX
SG_ BMMp_stat_Init : 0|1@1+ (1,0) [0|1] "" Vector__XXX
SG_ BMMp_stat_Standby : 1|1@1+ (1,0) [0|1] "" Vector__XXX
SG_ BMMp_stat_Precharge : 2|1@1+ (1,0) [0|1] "" Vector__XXX
SG_ BMMp_stat_Operational : 3|1@1+ (1,0) [0|1] "" Vector__XXX
SG_ BMMp_stat_Error : 6|1@1+ (1,0) [0|1] "" Vector__XXX
SG_ BMMp_flag_Drive : 8|1@1+ (1,0) [0|1] "" Vector__XXX
SG_ BMMp_flag_Charge : 9|1@1+ (1,0) [0|1] "" Vector__XXX
SG_ BMMp_flag_Wake : 16|1@1+ (1,0) [0|1] "" Vector__XXX
SG_ BMMp_flag_IsoDisable : 17|1@1+ (1,0) [0|1] "" Vector__XXX
SG_ BMMp_flag_ContactorHVPos : 19|1@1+ (1,0) [0|1] "" Vector__XXX
SG_ BMMp_flag_ContactorHVNeg : 20|1@1+ (1,0) [0|1] "" Vector__XXX
SG_ BMMp_flag_ContactorPrecha : 21|1@1+ (1,0) [0|1] "" Vector__XXX
SG_ BMMp_flag_ChargeComplete : 22|1@1+ (1,0) [0|1] "" Vector__XXX
SG_ BMMp_flag_ExternalSdwnRq : 23|1@1+ (1,0) [0|1] "" Vector__XXX
SG_ BMMp_flag_InternalKL30Safe : 24|1@1+ (1,0) [0|1] "" Vector__XXX
SG_ BMMp_flag_HVILState : 30|1@1+ (1,0) [0|1] "" Vector__XXX
SG_ BMMp_flag_eStopLoopClosed : 31|1@1+ (1,0) [0|1] "" Vector__XXX
SG_ BMMp_flag_Warning : 32|1@1+ (1,0) [0|1] "" Vector__XXX
SG_ BMMp_flag_Alarm : 33|1@1+ (1,0) [0|1] "" Vector__XXX
SG_ BMMp_flag_AuxCont : 34|1@1+ (1,0) [0|1] "" Vector__XXX
SG_ BMMp_flag_FireRisk : 39|1@1+ (1,0) [0|1] "" Vector__XXX
SG_ BMMp_cnt_AliveCounter : 48|8@1+ (1,0) [0|255] "" Vector__XXX
SG_ BMMp_cnt_MirroredAliveCounter : 56|8@1+ (1,0) [0|255] "" Vector__XXX

BO_ 2650820609 BMMp_IsolationResistance: 8 Vector__XXX
SG_ BMMp_act_R_IsoRes_kOhm : 0|16@1+ (1,0) [0|65535] "kOhm" Vector__XXX
SG_ BMMp_act_R_ActvIsoRPos_kOhm : 16|16@1+ (1,0) [0|65535] "kOhm" Vector__XXX
SG_ BMMp_act_R_ActvIsoRNeg_kOhm : 32|16@1+ (1,0) [0|65535] "kOhm" Vector__XXX
SG_ BMMp_stat_IsoResMeasStatus : 48|2@1+ (1,0) [0|3] "" Vector__XXX

BO_ 2650824705 BMMp_ErrorFlag: 8 Vector__XXX
SG_ BMMp_ef_CellVoltageMax : 0|1@1+ (1,0) [0|1] "" Vector__XXX
SG_ BMMp_ef_CellVoltageMin : 1|1@1+ (1,0) [0|1] "" Vector__XXX
SG_ BMMp_ef_SysVoltageMax : 2|1@1+ (1,0) [0|1] "" Vector__XXX
SG_ BMMp_ef_SysVoltageMin : 3|1@1+ (1,0) [0|1] "" Vector__XXX
SG_ BMMp_ef_SysVoltageSum : 4|1@1+ (1,0) [0|1] "" Vector__XXX
SG_ BMMp_ef_ModVoltageSum : 5|1@1+ (1,0) [0|1] "" Vector__XXX
SG_ BMMp_ef_ModVoltageRefMax : 6|1@1+ (1,0) [0|1] "" Vector__XXX
SG_ BMMp_ef_Mod_Voltage_Ref_Min : 7|1@1+ (1,0) [0|1] "" Vector__XXX
SG_ BMMp_ef_IsoFaultBattNeg : 8|1@1+ (1,0) [0|1] "" Vector__XXX
SG_ BMMp_ef_IsoFaultBattPos : 9|1@1+ (1,0) [0|1] "" Vector__XXX
SG_ BMMp_ef_ContactorNegStuck : 10|1@1+ (1,0) [0|1] "" Vector__XXX
SG_ BMMp_ef_ContactorPosStuck : 11|1@1+ (1,0) [0|1] "" Vector__XXX
SG_ BMMp_ef_LVSupplyMax : 12|1@1+ (1,0) [0|1] "" Vector__XXX
SG_ BMMp_ef_LVSupplyMin : 13|1@1+ (1,0) [0|1] "" Vector__XXX
SG_ BMMp_ef_TerminalTempMax : 14|1@1+ (1,0) [0|1] "" Vector__XXX
SG_ BMMp_ef_TerminalTempMin : 15|1@1+ (1,0) [0|1] "" Vector__XXX
SG_ BMMp_ef_CellTempChargMax : 16|1@1+ (1,0) [0|1] "" Vector__XXX
SG_ BMMp_ef_CellTempChargMin : 17|1@1+ (1,0) [0|1] "" Vector__XXX
SG_ BMMp_ef_CellTempDischMax : 18|1@1+ (1,0) [0|1] "" Vector__XXX
SG_ BMMp_ef_CellTempDischMin : 19|1@1+ (1,0) [0|1] "" Vector__XXX
SG_ BMMp_ef_SysCurCha : 20|1@1+ (1,0) [0|1] "" Vector__XXX
SG_ BMMp_ef_SysCurDis : 21|1@1+ (1,0) [0|1] "" Vector__XXX
SG_ BMMp_ef_HVCurrLoopMax : 22|1@1+ (1,0) [0|1] "" Vector__XXX
SG_ BMMp_ef_HVCurrLoopMin : 23|1@1+ (1,0) [0|1] "" Vector__XXX
SG_ BMMp_ef_eStopCurrLoopMax : 24|1@1+ (1,0) [0|1] "" Vector__XXX
SG_ BMMp_ef_eStopCurrLoopMin : 25|1@1+ (1,0) [0|1] "" Vector__XXX
SG_ BMMp_ef_SysCurLimitCha : 26|1@1+ (1,0) [0|1] "" Vector__XXX
SG_ BMMp_ef_SysCurLimitDis : 27|1@1+ (1,0) [0|1] "" Vector__XXX
SG_ BMMp_ef_SysPrechargeFailed : 28|1@1+ (1,0) [0|1] "" Vector__XXX
SG_ BMMp_ef_BMMBattCom : 29|1@1+ (1,0) [0|1] "" Vector__XXX
SG_ BMMp_ef_SysInitTimeout : 30|1@1+ (1,0) [0|1] "" Vector__XXX
SG_ BMMp_ef_SCUConfig : 31|1@1+ (1,0) [0|1] "" Vector__XXX
SG_ BMMp_ef_DeepDischProt : 32|1@1+ (1,0) [0|1] "" Vector__XXX
SG_ BMMp_ef_WDReset : 33|1@1+ (1,0) [0|1] "" Vector__XXX
SG_ BMMp_ef_ExtCommunicationTout : 34|1@1+ (1,0) [0|1] "" Vector__XXX
SG_ BMMp_ef_NoAfterrunTest : 35|1@1+ (1,0) [0|1] "" Vector__XXX
SG_ BMMp_ef_CellVoltUnbalance : 36|1@1+ (1,0) [0|1] "" Vector__XXX
SG_ BMMp_ef_CellTempUnbalance : 37|1@1+ (1,0) [0|1] "" Vector__XXX
SG_ BMMp_ef_TerminalTempUnbalance : 38|1@1+ (1,0) [0|1] "" Vector__XXX
SG_ BMMp_ef_LTCError : 39|1@1+ (1,0) [0|1] "" Vector__XXX
SG_ BMMp_ef_AfterrunTest : 40|1@1+ (1,0) [0|1] "" Vector__XXX
SG_ BMMp_ef_CrossCheck : 41|1@1+ (1,0) [0|1] "" Vector__XXX
SG_ BMMp_ef_StuckAtTemp : 42|1@1+ (1,0) [0|1] "" Vector__XXX
SG_ BMMp_ef_StuckAtVolt : 43|1@1+ (1,0) [0|1] "" Vector__XXX
SG_ BMMp_ef_ProgProcess : 44|1@1+ (1,0) [0|1] "" Vector__XXX
SG_ BMMp_ef_RAM : 45|1@1+ (1,0) [0|1] "" Vector__XXX
SG_ BMMp_ef_ROM : 46|1@1+ (1,0) [0|1] "" Vector__XXX
SG_ BMMp_ef_FlashEEPROM : 47|1@1+ (1,0) [0|1] "" Vector__XXX
SG_ BMMp_ef_InvalidData : 48|1@1+ (1,0) [0|1] "" Vector__XXX
SG_ BMMp_ef_ContactorWrongState : 49|1@1+ (1,0) [0|1] "" Vector__XXX
SG_ BMMp_ef_CurrSens : 50|1@1+ (1,0) [0|1] "" Vector__XXX
SG_ BMMp_ef_ContDam : 51|1@1+ (1,0) [0|1] "" Vector__XXX
SG_ BMMp_ef_RefVoltErrorMax : 52|1@1+ (1,0) [0|1] "" Vector__XXX
SG_ BMMp_ef_RefVoltErrorMin : 53|1@1+ (1,0) [0|1] "" Vector__XXX
SG_ BMMp_ef_KL30SafeMax : 54|1@1+ (1,0) [0|1] "" Vector__XXX
SG_ BMMp_ef_KL30SafeMin : 55|1@1+ (1,0) [0|1] "" Vector__XXX
SG_ BMMp_ef_CPUSupplyWarning : 56|1@1+ (1,0) [0|1] "" Vector__XXX
SG_ BMMp_ef_PowerProtectionWarning : 57|1@1+ (1,0) [0|1] "" Vector__XXX
SG_ BMMp_ef_KL30SafeOff : 58|1@1+ (1,0) [0|1] "" Vector__XXX
SG_ BMMp_ef_Dew_Sensor : 59|1@1+ (1,0) [0|1] "" Vector__XXX
SG_ BMMp_ef_ContactorDropOut : 60|1@1+ (1,0) [0|1] "" Vector__XXX
SG_ BMMp_ef_BoardTemp : 61|1@1+ (1,0) [0|1] "" Vector__XXX
SG_ BMMp_ef_SCUError : 63|1@1+ (1,0) [0|1] "" Vector__XXX

BO_ 2650828801 BMMp_AlarmFlag: 8 Vector__XXX
SG_ BMMp_af_CellVoltageMax : 0|1@1+ (1,0) [0|1] "" Vector__XXX
SG_ BMMp_af_CellVoltageMin : 1|1@1+ (1,0) [0|1] "" Vector__XXX
SG_ BMMp_af_SysVoltageMax : 2|1@1+ (1,0) [0|1] "" Vector__XXX
SG_ BMMp_af_SysVoltageMin : 3|1@1+ (1,0) [0|1] "" Vector__XXX
SG_ BMMp_af_SysVoltageSum : 4|1@1+ (1,0) [0|1] "" Vector__XXX
SG_ BMMp_af_ModVoltageSum : 5|1@1+ (1,0) [0|1] "" Vector__XXX
SG_ BMMp_af_ModVoltageRefMax : 6|1@1+ (1,0) [0|1] "" Vector__XXX
SG_ BMMp_af_Mod_Voltage_Ref_Min : 7|1@1+ (1,0) [0|1] "" Vector__XXX
SG_ BMMp_af_IsoFaultBattNeg : 8|1@1+ (1,0) [0|1] "" Vector__XXX
SG_ BMMp_af_IsoFaultBattPos : 9|1@1+ (1,0) [0|1] "" Vector__XXX
SG_ BMMp_af_ContactorNegStuck : 10|1@1+ (1,0) [0|1] "" Vector__XXX
SG_ BMMp_af_ContactorPosStuck : 11|1@1+ (1,0) [0|1] "" Vector__XXX
SG_ BMMp_af_LVSupplyMax : 12|1@1+ (1,0) [0|1] "" Vector__XXX
SG_ BMMp_af_LVSupplyMin : 13|1@1+ (1,0) [0|1] "" Vector__XXX
SG_ BMMp_af_TerminalTempMax : 14|1@1+ (1,0) [0|1] "" Vector__XXX
SG_ BMMp_af_TerminalTempMin : 15|1@1+ (1,0) [0|1] "" Vector__XXX
SG_ BMMp_af_CellTempChargMax : 16|1@1+ (1,0) [0|1] "" Vector__XXX
SG_ BMMp_af_CellTempChargMin : 17|1@1+ (1,0) [0|1] "" Vector__XXX
SG_ BMMp_af_CellTempDischMax : 18|1@1+ (1,0) [0|1] "" Vector__XXX
SG_ BMMp_af_CellTempDischMin : 19|1@1+ (1,0) [0|1] "" Vector__XXX
SG_ BMMp_af_SysCurCha : 20|1@1+ (1,0) [0|1] "" Vector__XXX
SG_ BMMp_af_SysCurDis : 21|1@1+ (1,0) [0|1] "" Vector__XXX
SG_ BMMp_af_HVCurrLoopMax : 22|1@1+ (1,0) [0|1] "" Vector__XXX
SG_ BMMp_af_HVCurrLoopMin : 23|1@1+ (1,0) [0|1] "" Vector__XXX
SG_ BMMp_af_eStopCurrLoopMax : 24|1@1+ (1,0) [0|1] "" Vector__XXX
SG_ BMMp_af_eStopCurrLoopMin : 25|1@1+ (1,0) [0|1] "" Vector__XXX
SG_ BMMp_af_SysCurLimitCha : 26|1@1+ (1,0) [0|1] "" Vector__XXX
SG_ BMMp_af_SysCurLimitDis : 27|1@1+ (1,0) [0|1] "" Vector__XXX
SG_ BMMp_af_SysPrechargeFailed : 28|1@1+ (1,0) [0|1] "" Vector__XXX
SG_ BMMp_af_BMMBattCom : 29|1@1+ (1,0) [0|1] "" Vector__XXX
SG_ BMMp_af_SysInitTimeout : 30|1@1+ (1,0) [0|1] "" Vector__XXX
SG_ BMMp_af_SCUConfig : 31|1@1+ (1,0) [0|1] "" Vector__XXX
SG_ BMMp_af_DeepDischProt : 32|1@1+ (1,0) [0|1] "" Vector__XXX
SG_ BMMp_af_WDReset : 33|1@1+ (1,0) [0|1] "" Vector__XXX
SG_ BMMp_af_ExtCommunicationTout : 34|1@1+ (1,0) [0|1] "" Vector__XXX
SG_ BMMp_af_NoAfterrunTest : 35|1@1+ (1,0) [0|1] "" Vector__XXX
SG_ BMMp_af_CellVoltUnbalance : 36|1@1+ (1,0) [0|1] "" Vector__XXX
SG_ BMMp_af_CellTempUnbalance : 37|1@1+ (1,0) [0|1] "" Vector__XXX
SG_ BMMp_af_TerminalTempUnbalance : 38|1@1+ (1,0) [0|1] "" Vector__XXX
SG_ BMMp_af_LTCError : 39|1@1+ (1,0) [0|1] "" Vector__XXX
SG_ BMMp_af_AfterrunTest : 40|1@1+ (1,0) [0|1] "" Vector__XXX
SG_ BMMp_af_CrossCheck : 41|1@1+ (1,0) [0|1] "" Vector__XXX
SG_ BMMp_af_StuckAtTemp : 42|1@1+ (1,0) [0|1] "" Vector__XXX
SG_ BMMp_af_StuckAtVolt : 43|1@1+ (1,0) [0|1] "" Vector__XXX
SG_ BMMp_af_ProgProcess : 44|1@1+ (1,0) [0|1] "" Vector__XXX
SG_ BMMp_af_RAM : 45|1@1+ (1,0) [0|1] "" Vector__XXX
SG_ BMMp_af_ROM : 46|1@1+ (1,0) [0|1] "" Vector__XXX
SG_ BMMp_af_FlashEEPROM : 47|1@1+ (1,0) [0|1] "" Vector__XXX
SG_ BMMp_af_InvalidData : 48|1@1+ (1,0) [0|1] "" Vector__XXX
SG_ BMMp_af_ContactorWrongState : 49|1@1+ (1,0) [0|1] "" Vector__XXX
SG_ BMMp_af_CurrSens : 50|1@1+ (1,0) [0|1] "" Vector__XXX
SG_ BMMp_af_ContDam : 51|1@1+ (1,0) [0|1] "" Vector__XXX
SG_ BMMp_af_RefVoltErrorMax : 52|1@1+ (1,0) [0|1] "" Vector__XXX
SG_ BMMp_af_RefVoltErrorMin : 53|1@1+ (1,0) [0|1] "" Vector__XXX
SG_ BMMp_af_KL30SafeMax : 54|1@1+ (1,0) [0|1] "" Vector__XXX
SG_ BMMp_af_KL30SafeMin : 55|1@1+ (1,0) [0|1] "" Vector__XXX
SG_ BMMp_af_CPUSupplyWarning : 56|1@1+ (1,0) [0|1] "" Vector__XXX
SG_ BMMp_af_PowerProtectionWarning : 57|1@1+ (1,0) [0|1] "" Vector__XXX
SG_ BMMp_af_KL30SafeOff : 58|1@1+ (1,0) [0|1] "" Vector__XXX
SG_ BMMp_af_Dew_Sensor : 59|1@1+ (1,0) [0|1] "" Vector__XXX
SG_ BMMp_af_ContactorDropOut : 60|1@1+ (1,0) [0|1] "" Vector__XXX
SG_ BMMp_af_BoardTemp : 61|1@1+ (1,0) [0|1] "" Vector__XXX
SG_ BMMp_af_SCUError : 63|1@1+ (1,0) [0|1] "" Vector__XXX

BO_ 2650832897 BMMp_WarningFlag: 8 Vector__XXX
SG_ BMMp_wf_CellVoltageMax : 0|1@1+ (1,0) [0|1] "" Vector__XXX
SG_ BMMp_wf_CellVoltageMin : 1|1@1+ (1,0) [0|1] "" Vector__XXX
SG_ BMMp_wf_SysVoltageMax : 2|1@1+ (1,0) [0|1] "" Vector__XXX
SG_ BMMp_wf_SysVoltageMin : 3|1@1+ (1,0) [0|1] "" Vector__XXX
SG_ BMMp_wf_SysVoltageSum : 4|1@1+ (1,0) [0|1] "" Vector__XXX
SG_ BMMp_wf_ModVoltageSum : 5|1@1+ (1,0) [0|1] "" Vector__XXX
SG_ BMMp_wf_ModVoltageRefMax : 6|1@1+ (1,0) [0|1] "" Vector__XXX
SG_ BMMp_wf_Mod_Voltage_Ref_Min : 7|1@1+ (1,0) [0|1] "" Vector__XXX
SG_ BMMp_wf_IsoFaultBattNeg : 8|1@1+ (1,0) [0|1] "" Vector__XXX
SG_ BMMp_wf_IsoFaultBattPos : 9|1@1+ (1,0) [0|1] "" Vector__XXX
SG_ BMMp_wf_ContactorNegStuck : 10|1@1+ (1,0) [0|1] "" Vector__XXX
SG_ BMMp_wf_ContactorPosStuck : 11|1@1+ (1,0) [0|1] "" Vector__XXX
SG_ BMMp_wf_LVSupplyMax : 12|1@1+ (1,0) [0|1] "" Vector__XXX
SG_ BMMp_wf_LVSupplyMin : 13|1@1+ (1,0) [0|1] "" Vector__XXX
SG_ BMMp_wf_TerminalTempMax : 14|1@1+ (1,0) [0|1] "" Vector__XXX
SG_ BMMp_wf_TerminalTempMin : 15|1@1+ (1,0) [0|1] "" Vector__XXX
SG_ BMMp_wf_CellTempChargMax : 16|1@1+ (1,0) [0|1] "" Vector__XXX
SG_ BMMp_wf_CellTempChargMin : 17|1@1+ (1,0) [0|1] "" Vector__XXX
SG_ BMMp_wf_CellTempDischMax : 18|1@1+ (1,0) [0|1] "" Vector__XXX
SG_ BMMp_wf_CellTempDischMin : 19|1@1+ (1,0) [0|1] "" Vector__XXX
SG_ BMMp_wf_SysCurCha : 20|1@1+ (1,0) [0|1] "" Vector__XXX
SG_ BMMp_wf_SysCurDis : 21|1@1+ (1,0) [0|1] "" Vector__XXX
SG_ BMMp_wf_HVCurrLoopMax : 22|1@1+ (1,0) [0|1] "" Vector__XXX
SG_ BMMp_wf_HVCurrLoopMin : 23|1@1+ (1,0) [0|1] "" Vector__XXX
SG_ BMMp_wf_eStopCurrLoopMax : 24|1@1+ (1,0) [0|1] "" Vector__XXX
SG_ BMMp_wf_eStopCurrLoopMin : 25|1@1+ (1,0) [0|1] "" Vector__XXX
SG_ BMMp_wf_SysCurLimitCha : 26|1@1+ (1,0) [0|1] "" Vector__XXX
SG_ BMMp_wf_SysCurLimitDis : 27|1@1+ (1,0) [0|1] "" Vector__XXX
SG_ BMMp_wf_SysPrechargeFailed : 28|1@1+ (1,0) [0|1] "" Vector__XXX
SG_ BMMp_wf_BMMBattCom : 29|1@1+ (1,0) [0|1] "" Vector__XXX
SG_ BMMp_wf_SysInitTimeout : 30|1@1+ (1,0) [0|1] "" Vector__XXX
SG_ BMMp_wf_SCUConfig : 31|1@1+ (1,0) [0|1] "" Vector__XXX
SG_ BMMp_wf_DeepDischProt : 32|1@1+ (1,0) [0|1] "" Vector__XXX
SG_ BMMp_wf_WDReset : 33|1@1+ (1,0) [0|1] "" Vector__XXX
SG_ BMMp_wf_ExtCommunicationTout : 34|1@1+ (1,0) [0|1] "" Vector__XXX
SG_ BMMp_wf_NoAfterrunTest : 35|1@1+ (1,0) [0|1] "" Vector__XXX
SG_ BMMp_wf_CellVoltUnbalance : 36|1@1+ (1,0) [0|1] "" Vector__XXX
SG_ BMMp_wf_CellTempUnbalance : 37|1@1+ (1,0) [0|1] "" Vector__XXX
SG_ BMMp_wf_TerminalTempUnbalance : 38|1@1+ (1,0) [0|1] "" Vector__XXX
SG_ BMMp_wf_LTCError : 39|1@1+ (1,0) [0|1] "" Vector__XXX
SG_ BMMp_wf_AfterrunTest : 40|1@1+ (1,0) [0|1] "" Vector__XXX
SG_ BMMp_wf_CrossCheck : 41|1@1+ (1,0) [0|1] "" Vector__XXX
SG_ BMMp_wf_StuckAtTemp : 42|1@1+ (1,0) [0|1] "" Vector__XXX
SG_ BMMp_wf_StuckAtVolt : 43|1@1+ (1,0) [0|1] "" Vector__XXX
SG_ BMMp_wf_ProgProcess : 44|1@1+ (1,0) [0|1] "" Vector__XXX
SG_ BMMp_wf_RAM : 45|1@1+ (1,0) [0|1] "" Vector__XXX
SG_ BMMp_wf_ROM : 46|1@1+ (1,0) [0|1] "" Vector__XXX
SG_ BMMp_wf_FlashEEPROM : 47|1@1+ (1,0) [0|1] "" Vector__XXX
SG_ BMMp_wf_InvalidData : 48|1@1+ (1,0) [0|1] "" Vector__XXX
SG_ BMMp_wf_ContactorWrongState : 49|1@1+ (1,0) [0|1] "" Vector__XXX
SG_ BMMp_wf_CurrSens : 50|1@1+ (1,0) [0|1] "" Vector__XXX
SG_ BMMp_wf_ContDam : 51|1@1+ (1,0) [0|1] "" Vector__XXX
SG_ BMMp_wf_RefVoltErrorMax : 52|1@1+ (1,0) [0|1] "" Vector__XXX
SG_ BMMp_wf_RefVoltErrorMin : 53|1@1+ (1,0) [0|1] "" Vector__XXX
SG_ BMMp_wf_KL30SafeMax : 54|1@1+ (1,0) [0|1] "" Vector__XXX
SG_ BMMp_wf_KL30SafeMin : 55|1@1+ (1,0) [0|1] "" Vector__XXX
SG_ BMMp_wf_CPUSupplyWarning : 56|1@1+ (1,0) [0|1] "" Vector__XXX
SG_ BMMp_wf_PowerProtectionWarning : 57|1@1+ (1,0) [0|1] "" Vector__XXX
SG_ BMMp_wf_KL30SafeOff : 58|1@1+ (1,0) [0|1] "" Vector__XXX
SG_ BMMp_wf_Dew_Sensor : 59|1@1+ (1,0) [0|1] "" Vector__XXX
SG_ BMMp_wf_ContactorDropOut : 60|1@1+ (1,0) [0|1] "" Vector__XXX
SG_ BMMp_wf_BoardTemp : 61|1@1+ (1,0) [0|1] "" Vector__XXX
SG_ BMMp_wf_SCUError : 63|1@1+ (1,0) [0|1] "" Vector__XXX

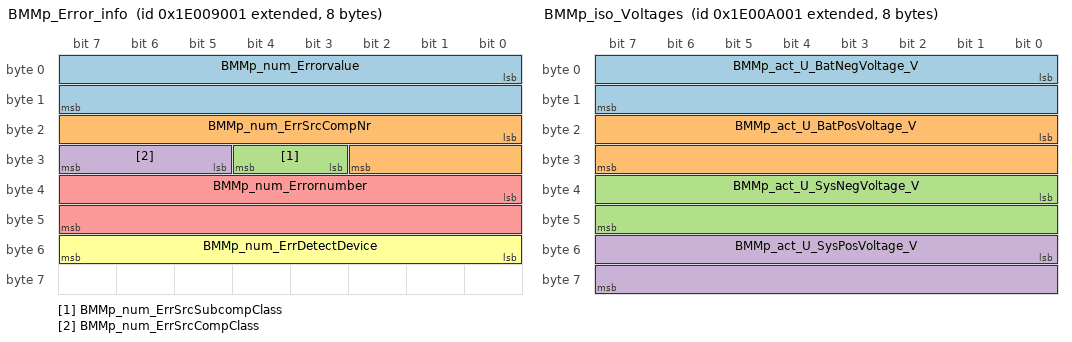
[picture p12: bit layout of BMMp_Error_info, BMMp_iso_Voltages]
BO_ 2650836993 BMMp_Error_info: 8 Vector__XXX
SG_ BMMp_num_Errorvalue : 0|16@1- (1,0) [-32768|32767] "" Vector__XXX
SG_ BMMp_num_ErrSrcCompNr : 16|11@1+ (1,0) [0|2047] "" Vector__XXX
SG_ BMMp_num_ErrSrcSubcompClass : 27|2@1+ (1,0) [0|3] "" Vector__XXX
SG_ BMMp_num_ErrSrcCompClass : 29|3@1+ (1,0) [0|7] "" Vector__XXX
SG_ BMMp_num_Errornumber : 32|16@1+ (1,0) [0|65535] "" Vector__XXX
SG_ BMMp_num_ErrDetectDevice : 48|8@1+ (1,0) [0|255] "" Vector__XXX

BO_ 2650841089 BMMp_iso_Voltages: 8 Vector__XXX
SG_ BMMp_act_U_BatNegVoltage_V : 0|16@1- (0.1,0) [-3276.8|3276.7] "V" Vector__XXX
SG_ BMMp_act_U_BatPosVoltage_V : 16|16@1- (0.1,0) [-3276.8|3276.7] "V" Vector__XXX
SG_ BMMp_act_U_SysNegVoltage_V : 32|16@1- (0.1,0) [-3276.8|3276.7] "V" Vector__XXX
SG_ BMMp_act_U_SysPosVoltage_V : 48|16@1- (0.1,0) [-3276.8|3276.7] "V" Vector__XXX

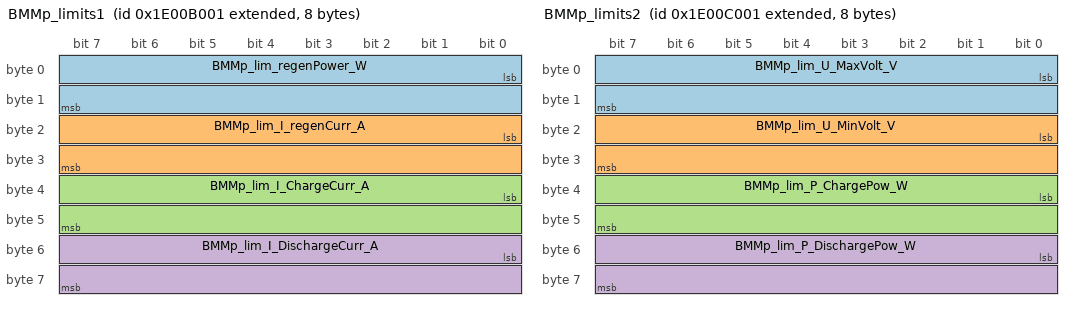
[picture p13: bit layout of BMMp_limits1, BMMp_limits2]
BO_ 2650845185 BMMp_limits1: 8 Vector__XXX
SG_ BMMp_lim_regenPower_W : 0|16@1+ (10,0) [0|655350] "W" Vector__XXX
SG_ BMMp_lim_I_regenCurr_A : 16|16@1+ (0.1,0) [0|6553.5] "A" Vector__XXX
SG_ BMMp_lim_I_ChargeCurr_A : 32|16@1+ (0.1,0) [0|6553.5] "A" Vector__XXX
SG_ BMMp_lim_I_DischargeCurr_A : 48|16@1+ (0.1,0) [0|6553.5] "A" Vector__XXX

BO_ 2650849281 BMMp_limits2: 8 Vector__XXX
SG_ BMMp_lim_U_MaxVolt_V : 0|16@1+ (0.1,0) [0|6553.5] "V" Vector__XXX
SG_ BMMp_lim_U_MinVolt_V : 16|16@1+ (0.1,0) [0|6553.5] "V" Vector__XXX
SG_ BMMp_lim_P_ChargePow_W : 32|16@1+ (10,0) [0|655350] "W" Vector__XXX
SG_ BMMp_lim_P_DischargePow_W : 48|16@1+ (10,0) [0|655350] "W" Vector__XXX

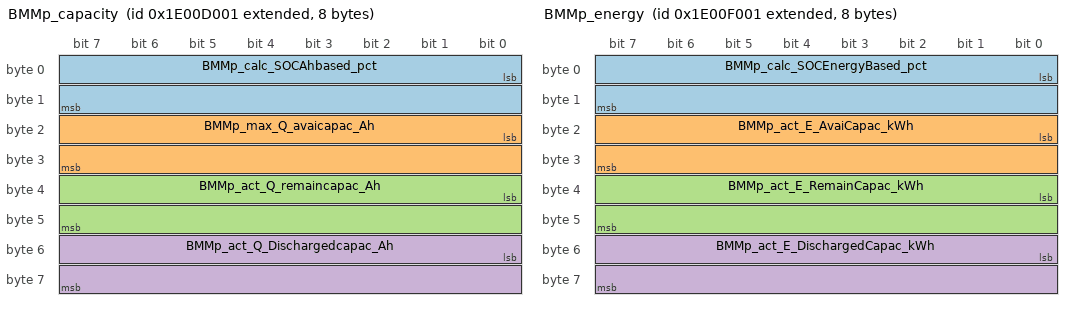
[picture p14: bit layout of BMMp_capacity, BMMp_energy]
BO_ 2650853377 BMMp_capacity: 8 Vector__XXX
SG_ BMMp_calc_SOCAhbased_pct : 0|16@1+ (0.0025,0) [0|163.8375] "%" Vector__XXX
SG_ BMMp_max_Q_avaicapac_Ah : 16|16@1+ (0.1,0) [0|6553.5] "Ah" Vector__XXX
SG_ BMMp_act_Q_remaincapac_Ah : 32|16@1- (0.1,0) [-3276.8|3276.7] "Ah" Vector__XXX
SG_ BMMp_act_Q_Dischargedcapac_Ah : 48|16@1+ (0.1,0) [0|6553.5] "Ah" Vector__XXX

BO_ 2650857473 BMMp_SOH: 8 Vector__XXX
SG_ BMMp_calc_SOHcapacity_pct : 0|16@1+ (0.1,0) [0|6553.5] "%" Vector__XXX
SG_ BMMp_calc_SOHimpedance_pct : 16|16@1+ (0.1,0) [0|6553.5] "%" Vector__XXX

BO_ 2650861569 BMMp_energy: 8 Vector__XXX
SG_ BMMp_calc_SOCEnergyBased_pct : 0|16@1+ (0.0025,0) [0|163.8375] "%" Vector__XXX
SG_ BMMp_act_E_AvaiCapac_kWh : 16|16@1+ (0.1,0) [0|6553.5] "kWh" Vector__XXX
SG_ BMMp_act_E_RemainCapac_kWh : 32|16@1- (0.1,0) [-3276.8|3276.7] "kWh" Vector__XXX
SG_ BMMp_act_E_DischargedCapac_kWh : 48|16@1+ (0.5,0) [0|32767.5] "kWh" Vector__XXX

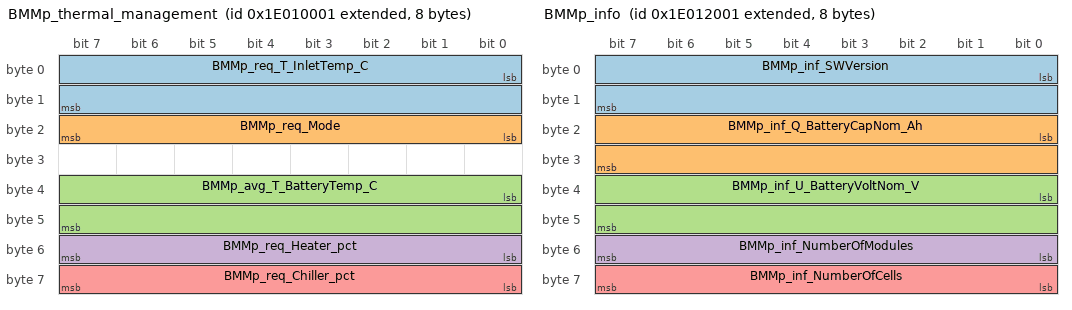
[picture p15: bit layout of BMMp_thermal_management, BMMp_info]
BO_ 2650865665 BMMp_thermal_management: 8 Vector__XXX
SG_ BMMp_req_T_InletTemp_C : 0|16@1- (0.1,0) [-3276.8|3276.7] "°C" Vector__XXX
SG_ BMMp_req_Mode : 16|8@1+ (1,0) [0|255] "1/Bit" Vector__XXX
SG_ BMMp_avg_T_BatteryTemp_C : 32|16@1- (0.1,0) [-3276.8|3276.7] "°C" Vector__XXX
SG_ BMMp_req_Heater_pct : 48|8@1+ (1,0) [0|255] "%" Vector__XXX
SG_ BMMp_req_Chiller_pct : 56|8@1+ (1,0) [0|255] "%" Vector__XXX

BO_ 2650869761 BMMp_info_thermal: 8 Vector__XXX
SG_ BMMp_act_T_CoolantTempIn_C : 16|16@1- (0.1,0) [-3276.8|3276.7] "°C" Vector__XXX
SG_ BMMp_act_T_CoolantTempOut_C : 32|16@1- (0.1,0) [-3276.8|3276.7] "°C" Vector__XXX

BO_ 2650873857 BMMp_info: 8 Vector__XXX
SG_ BMMp_inf_SWVersion : 0|16@1+ (1,0) [0|65535] "" Vector__XXX
SG_ BMMp_inf_Q_BatteryCapNom_Ah : 16|16@1+ (0.1,0) [0|6553.5] "Ah" Vector__XXX
SG_ BMMp_inf_U_BatteryVoltNom_V : 32|16@1+ (0.1,0) [0|6553.5] "V" Vector__XXX
SG_ BMMp_inf_NumberOfModules : 48|8@1+ (1,0) [0|255] "-" Vector__XXX
SG_ BMMp_inf_NumberOfCells : 56|8@1+ (1,0) [0|255] "-" Vector__XXX

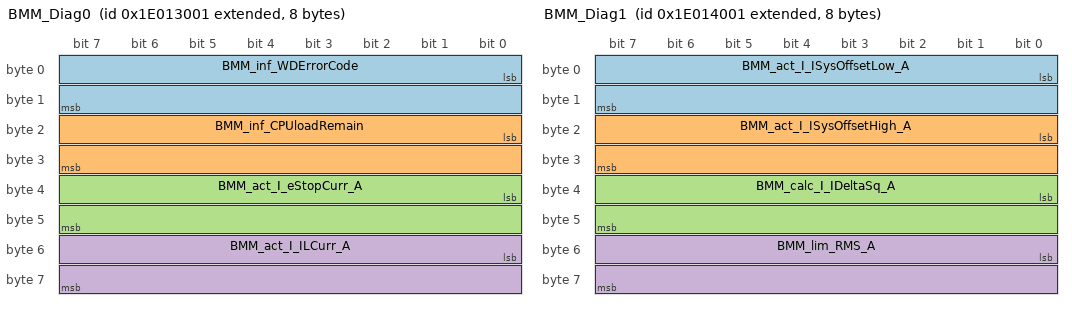
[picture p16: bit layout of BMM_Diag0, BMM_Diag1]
BO_ 2650877953 BMM_Diag0: 8 Vector__XXX
SG_ BMM_inf_WDErrorCode : 0|16@1+ (1,0) [0|65535] "" Vector__XXX
SG_ BMM_inf_CPUloadRemain : 16|16@1+ (1,0) [0|65535] "" Vector__XXX
SG_ BMM_act_I_eStopCurr_A : 32|16@1+ (1,0) [0|65535] "" Vector__XXX
SG_ BMM_act_I_ILCurr_A : 48|16@1+ (1,0) [0|65535] "" Vector__XXX

BO_ 2650882049 BMM_Diag1: 8 Vector__XXX
SG_ BMM_act_I_ISysOffsetLow_A : 0|16@1+ (0.1,0) [0|6553.5] "" Vector__XXX
SG_ BMM_act_I_ISysOffsetHigh_A : 16|16@1+ (0.1,0) [0|6553.5] "" Vector__XXX
SG_ BMM_calc_I_IDeltaSq_A : 32|16@1+ (0.1,0) [0|6553.5] "" Vector__XXX
SG_ BMM_lim_RMS_A : 48|16@1+ (0.1,0) [0|6553.5] "" Vector__XXX

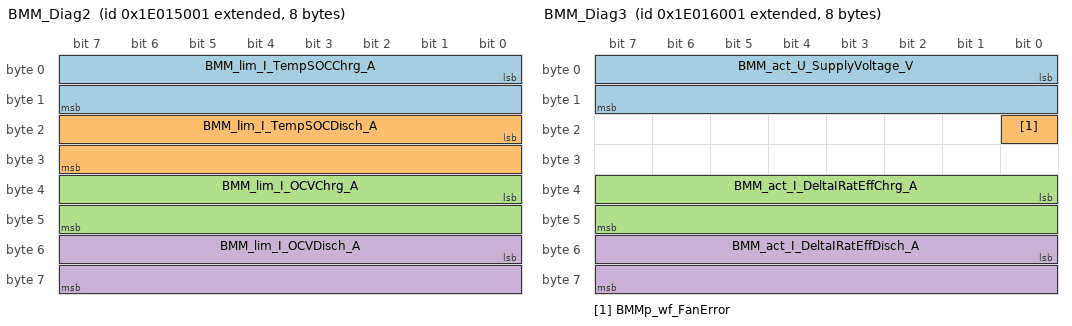
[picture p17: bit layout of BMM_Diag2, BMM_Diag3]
BO_ 2650886145 BMM_Diag2: 8 Vector__XXX
SG_ BMM_lim_I_TempSOCChrg_A : 0|16@1+ (0.1,0) [0|6553.5] "" Vector__XXX
SG_ BMM_lim_I_TempSOCDisch_A : 16|16@1+ (0.1,0) [0|6553.5] "" Vector__XXX
SG_ BMM_lim_I_OCVChrg_A : 32|16@1+ (0.1,0) [0|6553.5] "" Vector__XXX
SG_ BMM_lim_I_OCVDisch_A : 48|16@1+ (0.1,0) [0|6553.5] "" Vector__XXX

BO_ 2650890241 BMM_Diag3: 8 Vector__XXX
SG_ BMM_act_U_SupplyVoltage_V : 0|16@1+ (1,0) [0|65535] "" Vector__XXX
SG_ BMMp_wf_FanError : 16|1@1+ (1,0) [0|1] "" Vector__XXX
SG_ BMM_act_I_DeltaIRatEffChrg_A : 32|16@1+ (1,0) [0|65535] "" Vector__XXX
SG_ BMM_act_I_DeltaIRatEffDisch_A : 48|16@1+ (1,0) [0|65535] "" Vector__XXX

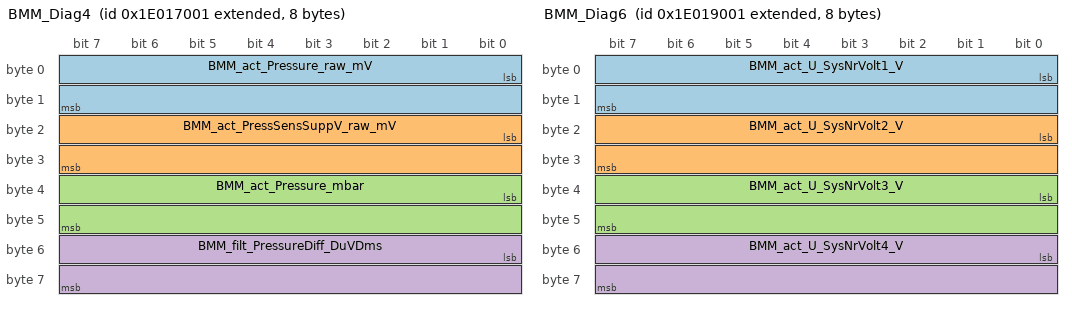
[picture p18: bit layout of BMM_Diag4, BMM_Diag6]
BO_ 2650894337 BMM_Diag4: 8 Vector__XXX
SG_ BMM_act_Pressure_raw_mV : 0|16@1+ (0.1,0) [0|6553.5] "mV" Vector__XXX
SG_ BMM_act_PressSensSuppV_raw_mV : 16|16@1+ (0.1,0) [0|6553.5] "mV" Vector__XXX
SG_ BMM_act_Pressure_mbar : 32|16@1+ (1,0) [0|65535] "mbar" Vector__XXX
SG_ BMM_filt_PressureDiff_DuVDms : 48|16@1- (1,0) [-32768|32767] "uV/ms" Vector__XXX

BO_ 2650898433 BMM_Diag5: 8 Vector__XXX
SG_ BMM_act_U_KL30SafeVolt_V : 0|16@1+ (0.1,0) [0|6553.5] "V" Vector__XXX

BO_ 2650902529 BMM_Diag6: 8 Vector__XXX
SG_ BMM_act_U_SysNrVolt1_V : 0|16@1+ (0.1,0) [0|6553.5] "V" Vector__XXX
SG_ BMM_act_U_SysNrVolt2_V : 16|16@1+ (0.1,0) [0|6553.5] "V" Vector__XXX
SG_ BMM_act_U_SysNrVolt3_V : 32|16@1+ (0.1,0) [0|6553.5] "V" Vector__XXX
SG_ BMM_act_U_SysNrVolt4_V : 48|16@1+ (0.1,0) [0|6553.5] "V" Vector__XXX

BO_ 2650906625 BMM_Diag7: 8 Vector__XXX
SG_ BMM_inf_Average_Core_Load : 0|16@1+ (0.1,0) [0|6553.5] "%" Vector__XXX
SG_ BMM_inf_Max_Core_Load : 16|16@1+ (0.1,0) [0|6553.5] "%" Vector__XXX

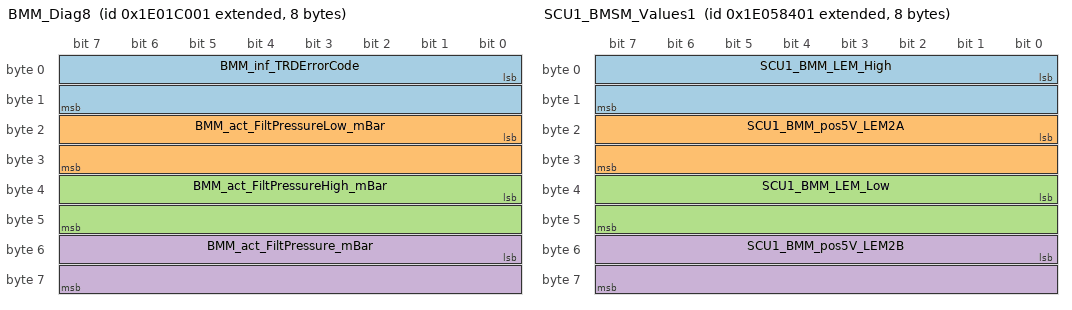
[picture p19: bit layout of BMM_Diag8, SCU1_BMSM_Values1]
BO_ 2650914817 BMM_Diag8: 8 Vector__XXX
SG_ BMM_inf_TRDErrorCode : 0|16@1+ (1,0) [0|65535] "" Vector__XXX
SG_ BMM_act_FiltPressureLow_mBar : 16|16@1- (0.1,0) [-3276.8|3276.7] "mbar" Vector__XXX
SG_ BMM_act_FiltPressureHigh_mBar : 32|16@1- (0.1,0) [-3276.8|3276.7] "mbar" Vector__XXX
SG_ BMM_act_FiltPressure_mBar : 48|16@1- (0.1,0) [-3276.8|3276.7] "mbar" Vector__XXX

BO_ 2651161601 SCU1_BMSM_Values1: 8 Vector__XXX
SG_ SCU1_BMM_LEM_High : 0|16@1- (0.1,0) [-3276.8|3276.7] "A" Vector__XXX
SG_ SCU1_BMM_pos5V_LEM2A : 16|16@1+ (1,0) [0|65535] "mV" Vector__XXX
SG_ SCU1_BMM_LEM_Low : 32|16@1- (0.1,0) [-3276.8|3276.7] "A" Vector__XXX
SG_ SCU1_BMM_pos5V_LEM2B : 48|16@1+ (1,0) [0|65535] "mV" Vector__XXX

BO_ 2651165697 SCU1_BMSM_Values2: 8 Vector__XXX
SG_ SCU1_BMM_Analog1 : 0|16@1+ (1,0) [0|65535] "mV" Vector__XXX
SG_ SCU1_BMM_Analog2 : 16|16@1+ (1,0) [0|65535] "mV" Vector__XXX
SG_ SCU1_BMM_HVIL_Current : 32|16@1+ (0.1,0) [0|6553.5] "mA" Vector__XXX
SG_ SCU1_BMM_eStop_Current : 48|16@1+ (0.1,0) [0|6553.5] "mA" Vector__XXX

BO_ 2651169793 SCU1_BMSM_Values3: 8 Vector__XXX
SG_ SCU1_BMM_KL30SafeIn : 0|16@1+ (0.001,0) [0|65.535] "V" Vector__XXX
SG_ SCU1_BMM_KL30SafeWDG : 16|16@1+ (0.001,0) [0|65.535] "V" Vector__XXX
SG_ SCU1_BMM_BMMSafePower : 32|16@1+ (0.001,0) [0|65.535] "V" Vector__XXX
SG_ SCU1_BMM_KL30 : 48|16@1+ (0.001,0) [0|65.535] "V" Vector__XXX

BO_ 2651173889 SCU1_BMSM_Values4: 8 Vector__XXX
SG_ SCU1_BMM_IS_BTS6163 : 0|16@1+ (1,0) [0|65535] "mV" Vector__XXX

BO_ 2651182081 BMU_Diag_Command: 8 Vector__XXX
SG_ Diag_Cmd : 0|16@1+ (1,0) [0|65535] "" Vector__XXX
SG_ Param1 : 16|16@1+ (1,0) [0|65535] "" Vector__XXX
SG_ Param2 : 32|32@1- (1,0) [-3.4E038|3.4E038] "" Vector__XXX

BO_ 2651186177 BMU_Simu_AD: 8 Vector__XXX
SG_ Simu_AD_Cmd : 0|16@1+ (1,0) [0|65535] "" Vector__XXX
SG_ AD_Channel : 16|16@1+ (1,0) [0|65535] "" Vector__XXX
SG_ Simu_Value : 32|32@1- (1,0) [-3.4E038|3.4E038] "" Vector__XXX

BO_ 2651190273 BMU_Simu_DIO: 8 Vector__XXX
SG_ Simu_DIO_Cmd : 0|16@1+ (1,0) [0|65535] "" Vector__XXX
SG_ DIO_Channel : 16|16@1+ (1,0) [0|65535] "" Vector__XXX
SG_ Simu_Value : 32|16@1+ (1,0) [0|65535] "" Vector__XXX

BO_ 2449585153 SCU1_Board_Supply_Vtg1: 8 Vector__XXX
SG_ SCU1_pos5V_LEM1A : 0|16@1- (1,0) [-32768|32767] "mV" Vector__XXX
SG_ SCU1_pos5V_LEM1B : 16|16@1- (1,0) [-32768|32767] "mV" Vector__XXX
SG_ SCU1_6Vpos : 32|16@1- (1,0) [-32768|32767] "mV" Vector__XXX
SG_ SCU1_6Vneg : 48|16@1- (1,0) [-32768|32767] "mV" Vector__XXX

BO_ 2449589249 SCU1_Board_Supply_Vtg2: 8 Vector__XXX
SG_ SCU1_pos5V : 0|16@1- (1,0) [-32768|32767] "mV" Vector__XXX

BO_ 2449593345 SCU1_HwConf_Adr_Vtg: 8 Vector__XXX
SG_ SCU1_Adr4 : 0|16@1+ (1,0) [0|65535] "mV" Vector__XXX
SG_ SCU1_Adr5 : 16|16@1+ (1,0) [0|65535] "mV" Vector__XXX
SG_ SCU1_HWConf0 : 32|16@1+ (1,0) [0|65535] "mV" Vector__XXX
SG_ SCU1_HWConf1 : 48|16@1+ (1,0) [0|65535] "mV" Vector__XXX

BO_ 2651331585 C001_SetCellMessage: 8 Vector__XXX
SG_ V001_set_U_CellVoltage_mV : 0|16@1+ (0.1,0) [0|6553.5] "mV" Vector__XXX
SG_ T001_set_T_CellTemp_C : 16|16@1- (0.01,0) [-327.68|327.67] "°C" Vector__XXX
SG_ V001_set_U_GPIOVoltage_mV : 32|16@1+ (0.1,0) [0|6553.5] "mV" Vector__XXX

BO_ 2651331586 C002_SetCellMessage: 8 Vector__XXX
SG_ V002_set_U_CellVoltage_mV : 0|16@1+ (0.1,0) [0|6553.5] "mV" Vector__XXX
SG_ T002_set_T_CellTemp_C : 16|16@1- (0.01,0) [-327.68|327.67] "°C" Vector__XXX
SG_ V002_set_U_GPIOVoltage_mV : 32|16@1+ (0.1,0) [0|6553.5] "mV" Vector__XXX

BO_ 2651331587 C003_SetCellMessage: 8 Vector__XXX
SG_ V003_set_U_CellVoltage_mV : 0|16@1+ (0.1,0) [0|6553.5] "mV" Vector__XXX
SG_ T003_set_T_CellTemp_C : 16|16@1- (0.01,0) [-327.68|327.67] "°C" Vector__XXX
SG_ V003_set_U_GPIOVoltage_mV : 32|16@1+ (0.1,0) [0|6553.5] "mV" Vector__XXX

BO_ 2651331588 C004_SetCellMessage: 8 Vector__XXX
SG_ V004_set_U_CellVoltage_mV : 0|16@1+ (0.1,0) [0|6553.5] "mV" Vector__XXX
SG_ T004_set_T_CellTemp_C : 16|16@1- (0.01,0) [-327.68|327.67] "°C" Vector__XXX
SG_ V004_set_U_GPIOVoltage_mV : 32|16@1+ (0.1,0) [0|6553.5] "mV" Vector__XXX

BO_ 2651331589 C005_SetCellMessage: 8 Vector__XXX
SG_ V005_set_U_CellVoltage_mV : 0|16@1+ (0.1,0) [0|6553.5] "mV" Vector__XXX
SG_ T005_set_T_CellTemp_C : 16|16@1- (0.01,0) [-327.68|327.67] "°C" Vector__XXX
SG_ V005_set_U_GPIOVoltage_mV : 32|16@1+ (0.1,0) [0|6553.5] "mV" Vector__XXX

BO_ 2651331590 C006_SetCellMessage: 8 Vector__XXX
SG_ V006_set_U_CellVoltage_mV : 0|16@1+ (0.1,0) [0|6553.5] "mV" Vector__XXX
SG_ T006_set_T_CellTemp_C : 16|16@1- (0.01,0) [-327.68|327.67] "°C" Vector__XXX
SG_ V006_set_U_GPIOVoltage_mV : 32|16@1+ (0.1,0) [0|6553.5] "mV" Vector__XXX

BO_ 2651331591 C007_SetCellMessage: 8 Vector__XXX
SG_ V007_set_U_CellVoltage_mV : 0|16@1+ (0.1,0) [0|6553.5] "mV" Vector__XXX
SG_ T007_set_T_CellTemp_C : 16|16@1- (0.01,0) [-327.68|327.67] "°C" Vector__XXX
SG_ V007_set_U_GPIOVoltage_mV : 32|16@1+ (0.1,0) [0|6553.5] "mV" Vector__XXX

BO_ 2651331592 C008_SetCellMessage: 8 Vector__XXX
SG_ V008_set_U_CellVoltage_mV : 0|16@1+ (0.1,0) [0|6553.5] "mV" Vector__XXX
SG_ T008_set_T_CellTemp_C : 16|16@1- (0.01,0) [-327.68|327.67] "°C" Vector__XXX
SG_ V008_set_U_GPIOVoltage_mV : 32|16@1+ (0.1,0) [0|6553.5] "mV" Vector__XXX

BO_ 2651331593 C009_SetCellMessage: 8 Vector__XXX
SG_ V009_set_U_CellVoltage_mV : 0|16@1+ (0.1,0) [0|6553.5] "mV" Vector__XXX
SG_ T009_set_T_CellTemp_C : 16|16@1- (0.01,0) [-327.68|327.67] "°C" Vector__XXX
SG_ V009_set_U_GPIOVoltage_mV : 32|16@1+ (0.1,0) [0|6553.5] "mV" Vector__XXX

BO_ 2651331594 C010_SetCellMessage: 8 Vector__XXX
SG_ V010_set_U_CellVoltage_mV : 0|16@1+ (0.1,0) [0|6553.5] "mV" Vector__XXX
SG_ T010_set_T_CellTemp_C : 16|16@1- (0.01,0) [-327.68|327.67] "°C" Vector__XXX
SG_ V010_set_U_GPIOVoltage_mV : 32|16@1+ (0.1,0) [0|6553.5] "mV" Vector__XXX

BO_ 2651331595 C011_SetCellMessage: 8 Vector__XXX
SG_ V011_set_U_CellVoltage_mV : 0|16@1+ (0.1,0) [0|6553.5] "mV" Vector__XXX
SG_ T011_set_T_CellTemp_C : 16|16@1- (0.01,0) [-327.68|327.67] "°C" Vector__XXX
SG_ V011_set_U_GPIOVoltage_mV : 32|16@1+ (0.1,0) [0|6553.5] "mV" Vector__XXX

BO_ 2651331596 C012_SetCellMessage: 8 Vector__XXX
SG_ V012_set_U_CellVoltage_mV : 0|16@1+ (0.1,0) [0|6553.5] "mV" Vector__XXX
SG_ T012_set_T_CellTemp_C : 16|16@1- (0.01,0) [-327.68|327.67] "°C" Vector__XXX
SG_ V012_set_U_GPIOVoltage_mV : 32|16@1+ (0.1,0) [0|6553.5] "mV" Vector__XXX

BO_ 2651331597 C013_SetCellMessage: 8 Vector__XXX
SG_ V013_set_U_CellVoltage_mV : 0|16@1+ (0.1,0) [0|6553.5] "mV" Vector__XXX
SG_ T013_set_T_CellTemp_C : 16|16@1- (0.01,0) [-327.68|327.67] "°C" Vector__XXX
SG_ V013_set_U_GPIOVoltage_mV : 32|16@1+ (0.1,0) [0|6553.5] "mV" Vector__XXX

BO_ 2651331598 C014_SetCellMessage: 8 Vector__XXX
SG_ V014_set_U_CellVoltage_mV : 0|16@1+ (0.1,0) [0|6553.5] "mV" Vector__XXX
SG_ T014_set_T_CellTemp_C : 16|16@1- (0.01,0) [-327.68|327.67] "°C" Vector__XXX
SG_ V014_set_U_GPIOVoltage_mV : 32|16@1+ (0.1,0) [0|6553.5] "mV" Vector__XXX

BO_ 2651331599 C015_SetCellMessage: 8 Vector__XXX
SG_ V015_set_U_CellVoltage_mV : 0|16@1+ (0.1,0) [0|6553.5] "mV" Vector__XXX
SG_ T015_set_T_CellTemp_C : 16|16@1- (0.01,0) [-327.68|327.67] "°C" Vector__XXX
SG_ V015_set_U_GPIOVoltage_mV : 32|16@1+ (0.1,0) [0|6553.5] "mV" Vector__XXX

BO_ 2651331600 C016_SetCellMessage: 8 Vector__XXX
SG_ V016_set_U_CellVoltage_mV : 0|16@1+ (0.1,0) [0|6553.5] "mV" Vector__XXX
SG_ T016_set_T_CellTemp_C : 16|16@1- (0.01,0) [-327.68|327.67] "°C" Vector__XXX
SG_ V016_set_U_GPIOVoltage_mV : 32|16@1+ (0.1,0) [0|6553.5] "mV" Vector__XXX

BO_ 2651331601 C017_SetCellMessage: 8 Vector__XXX
SG_ V017_set_U_CellVoltage_mV : 0|16@1+ (0.1,0) [0|6553.5] "mV" Vector__XXX
SG_ T017_set_T_CellTemp_C : 16|16@1- (0.01,0) [-327.68|327.67] "°C" Vector__XXX
SG_ V017_set_U_GPIOVoltage_mV : 32|16@1+ (0.1,0) [0|6553.5] "mV" Vector__XXX

BO_ 2651331602 C018_SetCellMessage: 8 Vector__XXX
SG_ V018_set_U_CellVoltage_mV : 0|16@1+ (0.1,0) [0|6553.5] "mV" Vector__XXX
SG_ T018_set_T_CellTemp_C : 16|16@1- (0.01,0) [-327.68|327.67] "°C" Vector__XXX
SG_ V018_set_U_GPIOVoltage_mV : 32|16@1+ (0.1,0) [0|6553.5] "mV" Vector__XXX

BO_ 2651331603 C019_SetCellMessage: 8 Vector__XXX
SG_ V019_set_U_CellVoltage_mV : 0|16@1+ (0.1,0) [0|6553.5] "mV" Vector__XXX
SG_ T019_set_T_CellTemp_C : 16|16@1- (0.01,0) [-327.68|327.67] "°C" Vector__XXX
SG_ V019_set_U_GPIOVoltage_mV : 32|16@1+ (0.1,0) [0|6553.5] "mV" Vector__XXX

BO_ 2651331604 C020_SetCellMessage: 8 Vector__XXX
SG_ V020_set_U_CellVoltage_mV : 0|16@1+ (0.1,0) [0|6553.5] "mV" Vector__XXX
SG_ T020_set_T_CellTemp_C : 16|16@1- (0.01,0) [-327.68|327.67] "°C" Vector__XXX
SG_ V020_set_U_GPIOVoltage_mV : 32|16@1+ (0.1,0) [0|6553.5] "mV" Vector__XXX

BO_ 2651404289 M001_WriteEEPROMData_LTC: 8 Vector__XXX
SG_ M001_val_EEPROMWriteLength : 0|8@1+ (1,0) [0|255] "" Vector__XXX
SG_ M001_val_EEPROMWriteIndex : 8|8@1+ (1,0) [0|255] "" Vector__XXX
SG_ M001_val_EEPROMWriteAdress : 16|16@1+ (1,0) [0|65535] "" Vector__XXX
SG_ M001_val_EEPROMWriteData : 32|32@1+ (1,0) [0|4294967295] "" Vector__XXX

BO_ 2651404545 M001_ReadEEPROMData_LTC: 8 Vector__XXX
SG_ M001_ReadEEPROMData_LTC_Mux M : 0|8@1+ (1,0) [0|0] "" Vector__XXX
SG_ M001_val_EEPROMWriteArea m255 : 8|8@1+ (1,0) [0|255] "" Vector__XXX
SG_ M001_val_EEPROMWriteAdress m255 : 24|8@1+ (1,0) [0|255] "" Vector__XXX
SG_ M001_val_EEPROMWriteData m255 : 32|32@1+ (1,0) [0|4294967295] "" Vector__XXX

CM_ BO_ 2449527809 "SCU alarm message (SCU alarm message)";
CM_ SG_ 2449527809 SCU1_af_InvalidData "short circuit or open temperature sensor";
CM_ SG_ 2449527809 SCU1_af_ContactorWrongState "tbd";
CM_ SG_ 2449527809 SCU1_af_CurrSens "i sensor error occurred";
CM_ SG_ 2449527809 SCU1_af_ContDam "contactors damaged";
CM_ SG_ 2449527809 SCU1_af_RefVoltErrorMax "refernce voltage to high";
CM_ SG_ 2449527809 SCU1_af_RefVoltErrorMin "refernce voltage to low";
CM_ SG_ 2449527809 SCU1_af_KL30SafeMax "KL30-Safe max";
CM_ SG_ 2449527809 SCU1_af_KL30SafeMin "KL30-Safe min";
CM_ SG_ 2449527809 SCU1_af_KL30SafeOff "BMS-M-SafePwr was switched off (HW detection)";
CM_ SG_ 2449527809 SCU1_af_ContactorDropOut "a contactor drop out occured";
CM_ SG_ 2449527809 SCU1_af_BoardTemp "ECU/IC board temperature too high/low";
CM_ BO_ 2316833792 "Control digital outputs (Control digital outputs)";
CM_ SG_ 2316833792 BMM_req_ContactorPos "contactor +";
CM_ SG_ 2316833792 BMM_req_ContactorNeg "contactor -";
CM_ SG_ 2316833792 BMM_req_ContactorPre "precharge contactor";
CM_ SG_ 2316833792 BMM_req_ContactorAux "aux contactors";
CM_ SG_ 2316833792 BMM_req_VSenseRelayBatPos "V sense Relay Bat+";
CM_ SG_ 2316833792 BMM_req_VSenseRelayBatNeg "V sense Relay Bat-";
CM_ SG_ 2316833792 BMM_req_VSenseRelaySysPos "V sense Relay Sys+";
CM_ SG_ 2316833792 BMM_req_VSenseRelaySysNeg "V sense Relay Sys-";
CM_ SG_ 2316833792 BMM_Fan_State "Stafe of the fan";
CM_ BO_ 2651595777 "Control digital outputs diagnostic (Control digital outputs diagnostic)";
CM_ SG_ 2651595777 SCU1_req_ContactorPosDiag "request for contactor + diagnostic";
CM_ SG_ 2651595777 SCU1_req_ContactorNegDiag "request for contactor - diagnostic";
CM_ SG_ 2651595777 SCU1_req_ContactorPreDiag "request for precharge contactor diagnostic";
CM_ SG_ 2651595777 SCU1_req_ContactorAuxDiag "request for extended aux contactor diagnostic";
CM_ SG_ 2651595777 SCU1_req_VSenseRelayBatPosDiag "request for Sense relay Tray+ extern diagnostic";
CM_ SG_ 2651595777 SCU1_req_VSenseRelayBatNegDiag "request for Sense relay Tray- extern diagnostic";
CM_ SG_ 2651595777 SCU1_req_VSenseRelaySysPosDiag "request for Sense relay Tray+ intern diagnostic";
CM_ SG_ 2651595777 SCU1_req_VSenseRelaySysNegDiag "request for Sense relay Tray- intern diagnostic";
CM_ SG_ 2651595777 SCU1_req_ShutdownDiag "request to swirch off SCU hardware";
CM_ SG_ 2651595777 SCU1_req_CANGatewayDiag "request to swirch on / off the CAN gateway";
CM_ SG_ 2651595777 SCU1_req_eStopBrakeOutDiag "request to swirch on / off the eStop brake out";
CM_ SG_ 2651595777 SCU1_req_InterlockSourceDiag "request to swirch on / off the interlock source";
CM_ SG_ 2651595777 SCU1_req_WdgTrigOffDiag "request to stop the external watchdog trigger";
CM_ SG_ 2651595777 SCU1_req_SafetyEnable1Diag "request to swirch on / off the safety enable 1";
CM_ SG_ 2651595777 SCU1_req_SafetyEnable2Diag "request to swirch on / off the safety enable 2";
CM_ SG_ 2651595777 SCU1_req_BMSPowerDiag "request to swirch on / off the BMS power";
CM_ SG_ 2651595777 SCU1_req_SystemResetDiag "request to generate a software reset";
CM_ SG_ 2651595777 SCU1_req_LEDDiag "not used";
CM_ SG_ 2651595777 SCU1_req_WdgTrigFastDiag "request to generate a fast watchdog trigger to generate an external watchdog";
CM_ SG_ 2651595777 SCU1_req_WdgAlarmResetDiag "request to disable the internal watchdog trigger";
CM_ BO_ 2451055617 "Operate highside switch outputs in";
CM_ SG_ 2451055617 SCU1_req_HSOutput1_pct "Highside-Switch-Output 1  Request";
CM_ SG_ 2451055617 SCU1_req_HSOutput2_pct "Highside-Switch-Output 2  Request";
CM_ SG_ 2451055617 SCU1_req_HSOutput3_pct "Highside-Switch-Output 3  Request";
CM_ SG_ 2451055617 SCU1_req_HSOutput4_pct "Highside-Switch-Output 4  Request";
CM_ BO_ 2449540097 "SCU SW configuration information (SCU SW configuration information)";
CM_ SG_ 2449540097 SCU1_inf_NumOfModule "number of modules";
CM_ SG_ 2449540097 SCU1_inf_NumOfCell "number of serial cells per module";
CM_ SG_ 2449540097 SCU1_inf_Checksum "checksum of the software configuration";
CM_ BO_ 2449552385 "SCU limit configuration information (SCU limit configuration information)";
CM_ SG_ 2449552385 SCU1_lim_U_MinVolt_V "minimun voltage limit";
CM_ SG_ 2449552385 SCU1_lim_U_MaxVolt_V "maximum voltage limit";
CM_ SG_ 2449552385 SCU1_lim_T_MinTemp_C "minimum temperature limit";
CM_ SG_ 2449552385 SCU1_lim_T_MaxTemp_C "maximum temperature limit";
CM_ BO_ 2449556481 "SCU tray configuration information (SCU tray configuration information)";
CM_ SG_ 2449556481 SCU1_inf_LowCellNr "lowest monitored cell number";
CM_ SG_ 2449556481 SCU1_inf_HighCellNr "highest monitored cell number";
CM_ SG_ 2449556481 SCU1_inf_LowModNr "lowest monitored module number";
CM_ SG_ 2449556481 SCU1_inf_HighModNr "highest monitored module number";
CM_ BO_ 2348811265 "SCU gateway test message (SCU gateway test message)";
CM_ BO_ 2651067393 "SCU Raw Value message 1 (SCU Raw Value message 1)";
CM_ SG_ 2651067393 SCU1_raw_KL30Voltage "ADC raw value of KL30 voltage";
CM_ SG_ 2651067393 SCU1_raw_BMMSafeVoltage "ADC raw value of BMM Safe voltage";
CM_ SG_ 2651067393 SCU1_raw_HSS12Voltage "ADC raw value of HSS12 voltage";
CM_ SG_ 2651067393 SCU1_raw_ReferenceVoltage "ADC raw value of SCU reference voltage";
CM_ BO_ 2651071489 "SCU Raw Value message 2 (SCU Raw Value message 2)";
CM_ SG_ 2651071489 SCU1_raw_HSS34Voltage "ADC raw value of HSS34 voltage";
CM_ SG_ 2651071489 SCU1_raw_TrayBatVoltPos "ADC raw value of bat pos voltage";
CM_ SG_ 2651071489 SCU1_raw_TrayBatVoltNeg "ADC raw value of bat neg voltage";
CM_ SG_ 2651071489 SCU1_raw_TraySysVoltPos "ADC raw value of Sys pos voltage";
CM_ BO_ 2651075585 "SCU Raw Value message 3 (SCU Raw Value message 3)";
CM_ SG_ 2651075585 SCU1_raw_TraySysVoltNeg "ADC raw value of Sys neg voltage";
CM_ SG_ 2651075585 SCU1_raw_TrayGndVolt "ADC raw value of gnd voltage";
CM_ SG_ 2651075585 SCU1_raw_ExtSense1 "ADC raw value of external sense 1";
CM_ SG_ 2651075585 SCU1_raw_ExtSense2 "ADC raw value of external sense 2";
CM_ BO_ 2651079681 "SCU Raw Value message 4 (SCU Raw Value message 4)";
CM_ SG_ 2651079681 SCU1_raw_ContPosCoilCurr "ADC raw value of pos contactor coil current";
CM_ SG_ 2651079681 SCU1_raw_ContNegCoilCurr "ADC raw value of neg contactor coil current";
CM_ SG_ 2651079681 SCU1_raw_ContPreCoilCurr "ADC raw value of pre contactor coil current";
CM_ SG_ 2651079681 SCU1_raw_ContExtAuxCoilCurr "ADC raw value of extaux contactor coil current";
CM_ BO_ 2651083777 "SCU Raw Value message 5 (SCU Raw Value message 5)";
CM_ SG_ 2651083777 SCU1_raw_ISenseLowCurr "ADC raw value of current sensor low channel";
CM_ SG_ 2651083777 SCU1_raw_ISenseHighCurr "ADC raw value of current sensor high channel";
CM_ SG_ 2651083777 SCU1_raw_eStopLoopCurr "ADC raw value of eStopLoop Current";
CM_ SG_ 2651083777 SCU1_raw_ILockLoopCurr "ADC raw value of interlock Current";
CM_ BO_ 2651087873 "SCU Raw Value message 6 (SCU Raw Value message 6)";
CM_ SG_ 2651087873 SCU1_raw_HSSwitch1Curr "ADC raw value of high side switch 1";
CM_ SG_ 2651087873 SCU1_raw_HSSwitch2Curr "ADC raw value of high side switch 2";
CM_ SG_ 2651087873 SCU1_raw_HSSwitch3Curr "ADC raw value of high side switch 3";
CM_ SG_ 2651087873 SCU1_raw_HSSwitch4Curr "ADC raw value of high side switch 4";
CM_ BO_ 2651091969 "SCU Raw Value message 7 (SCU Raw Value message 7)";
CM_ SG_ 2651091969 SCU1_raw_CPULoadAvg "Scu cycle load";
CM_ SG_ 2651091969 SCU1_raw_TrayVoltage "ADC raw value of scu tray voltage";
CM_ SG_ 2651091969 SCU1_raw_TrayTemp "ADC raw value of scu board temperature";
CM_ SG_ 2651091969 SCU1_raw_CPULoadMax "Scu max cycle load";
CM_ BO_ 2651096065 "SCU Raw Value message 8 (SCU Raw Value message 8)";
CM_ SG_ 2651096065 SCU1_raw_MagneticMarker "calculated value of the magnetic marker";
CM_ SG_ 2651096065 SCU1_raw_HysteresisOffset "calculated value of the hysteresis offset";
CM_ SG_ 2651096065 SCU1_raw_NonOffsetIHighChannel "current sensor high channel without offset";
CM_ SG_ 2651096065 SCU1_raw_ActOffsetIHighChannel "actual offset of current sensor high channel";
CM_ BO_ 2651100161 "SCU Raw Value message 9 for SCU hardware test (SCU Raw Value message 9 for SCU hardware test)";
CM_ SG_ 2651100161 SCU1_raw_DIO_P02_00_In "DIin_Forced_Save_State";
CM_ SG_ 2651100161 SCU1_raw_DIO_P02_01_In "DIin_BMS_S_Safe_State";
CM_ SG_ 2651100161 SCU1_raw_DIO_P02_02_In "DIin_KL15_WAKE";
CM_ SG_ 2651100161 SCU1_raw_DIO_P02_05_Out "DIin_HW_Version_Bit_0";
CM_ SG_ 2651100161 SCU1_raw_DIO_P02_06_In "DIin_HW_Version_Bit_1";
CM_ SG_ 2651100161 SCU1_raw_DIO_P02_07_In "DIin_KL30_Safe_OK";
CM_ SG_ 2651100161 SCU1_raw_DIO_P02_12_Out "DIout_CAN_Gateway";
CM_ SG_ 2651100161 SCU1_raw_DIO_P03_03_Out "DIout_SPI_1_CS_0      Chip select 0 am SPI Bus 1";
CM_ SG_ 2651100161 SCU1_raw_DIO_P03_04_Out "DIout_SPI_1_CS_1      Chip select 1 am SPI Bus 1";
CM_ SG_ 2651100161 SCU1_raw_DIO_P04_04_Out "DIout_HV_MR_BatPlus   HV-Messrelais Bat+";
CM_ SG_ 2651100161 SCU1_raw_DIO_P04_05_Out "DIout_HV_MR_BatMinus  HV-Messrelais Bat-";
CM_ SG_ 2651100161 SCU1_raw_DIO_P04_06_Out "DIout_HV_MR_SysPlus   HV-Messrelais Sys+";
CM_ SG_ 2651100161 SCU1_raw_DIO_P04_07_Out "DIout_HV_MR_SysMinus  HV-Messrelais Sys-";
CM_ SG_ 2651100161 SCU1_raw_DIO_P06_02_Out "DIout_eStop_Brake_Out";
CM_ SG_ 2651100161 SCU1_raw_DIO_P06_03_Out "DIout_Safety_Enable2";
CM_ SG_ 2651100161 SCU1_raw_DIO_P07_01_Out "DIout_Safety_Enable1";
CM_ SG_ 2651100161 SCU1_raw_DIO_P07_02_Out "DIout_External_Watchdog";
CM_ SG_ 2651100161 SCU1_raw_DIO_P08_03_Out "DIout_HS_Switch_1";
CM_ SG_ 2651100161 SCU1_raw_DIO_P08_04_Out "DIout_HS_Switch_2";
CM_ SG_ 2651100161 SCU1_raw_DIO_P08_05_Out "DIout_HS_Switch_3";
CM_ SG_ 2651100161 SCU1_raw_DIO_P08_06_Out "DIout_HS_Switch_4";
CM_ SG_ 2651100161 SCU1_raw_DIO_P09_00_BiIO "DIout_Alive_LED";
CM_ SG_ 2651100161 SCU1_raw_DIO_P09_01_Out "DIout_Debug_LED";
CM_ SG_ 2651100161 SCU1_raw_DIO_P09_02_Out "DIout_Error_LED";
CM_ SG_ 2651100161 SCU1_raw_DIO_P09_03_Out "DIio_OW_Port_1     on wire bus no 1";
CM_ SG_ 2651100161 SCU1_raw_DIO_P09_04_Out "DIout_Con_HV_plus";
CM_ SG_ 2651100161 SCU1_raw_DIO_P09_05_BiIO "DIout_Con_HV_minus";
CM_ SG_ 2651100161 SCU1_raw_DIO_P09_06_BiIO "DIout_Con_Precharge";
CM_ SG_ 2651100161 SCU1_raw_DIO_P09_07_BiIO "DIout_Con_Ext_Aux";
CM_ SG_ 2651100161 SCU1_raw_DIO_P10_08_BiIO "DIio_ExtID_Bit0";
CM_ SG_ 2651100161 SCU1_raw_DIO_P10_09_BiIO "DIio_ExtID_Bit1";
CM_ SG_ 2651100161 SCU1_raw_DIO_P10_10_Out "DIio_ExtID_Bit2";
CM_ SG_ 2651100161 SCU1_raw_DIO_P10_11_Out "DIio_ExtID_Bit3";
CM_ SG_ 2651100161 SCU1_raw_DIO_P10_12_Out "DIio_ExtID_Bit4";
CM_ SG_ 2651100161 SCU1_raw_DIO_P11_02_Out "DIout_Interlock_SrcOn";
CM_ SG_ 2651100161 SCU1_raw_DIO_P11_03_Out "DIout_Interlock_HC";
CM_ SG_ 2651100161 SCU1_raw_DIO_P11_04_Out "DIout_SCU_Power";
CM_ SG_ 2651100161 SCU1_raw_DIO_P11_05_Out "DIout_BMS_Power";
CM_ SG_ 2651100161 SCU1_raw_DIO_ESR0_In "DIin_Comp_Chip_Warning";
CM_ SG_ 2651100161 SCU1_raw_DIO_ESR1_In "DIin_CPU_Supply_Warning";
CM_ SG_ 2651100161 SCU1_raw_DIO_ESR2_In "DIin_Power_Protection_Warning";
CM_ BO_ 2651104257 "SCU Raw Value message 10  for SCU hardware test (SCU Raw Value message 10  for SCU hardware test)";
CM_ SG_ 2651104257 SCU1_raw_ID_bit_0 "Input of SCU ID 0";
CM_ SG_ 2651104257 SCU1_raw_ID_bit_1 "Input of SCU ID 1";
CM_ SG_ 2651104257 SCU1_raw_ID_bit_2 "Input of SCU ID 2";
CM_ SG_ 2651104257 SCU1_raw_ID_bit_3 "Input of SCU ID 3";
CM_ SG_ 2651104257 SCU1_raw_ID_bit_4 "Input of SCU ID 4";
CM_ SG_ 2651104257 SCU1_raw_ID_Combi "SCU ID combination no.";
CM_ SG_ 2651104257 SCU1_raw_U1_BMSCAN "cell test voltage of cell 1";
CM_ SG_ 2651104257 SCU1_raw_T1_BMSCAN "cell test temperature of cell 1";
CM_ SG_ 2651104257 SCU1_raw_Watchdog_Alarm_bit_0 "watchdog alarm bit of external watchdog";
CM_ SG_ 2651104257 SCU1_raw_Watchdog_Alarm_bit_1 "watchdog alarm bit of internal watchdog";
CM_ BO_ 2651063297 "SCU Raw Error Value message (SCU Raw Error Value message)";
CM_ SG_ 2651063297 SCU1_raw_ErrorNumber "error number";
CM_ SG_ 2651063297 SCU1_raw_ErrorParameter1 "error parameter 1";
CM_ SG_ 2651063297 SCU1_raw_ErrorParameter2 "error parameter 2";
CM_ SG_ 2651063297 SCU1_raw_ErrorCodePosition "error code position";
CM_ BO_ 2651587585 "SCU diagnostic function activation message (SCU diagnostic function activation message)";
CM_ SG_ 2651587585 SCU1_val_DiagActivationID "Activation ID";
CM_ BO_ 2181563392 "SCU synchinization message (SCU synchinization message)";
CM_ BO_ 2315342849 "Damage of contactors (Damage of contactors)";
CM_ SG_ 2315342849 SCU1_ctr_DamageTotal "contactor damage";
CM_ BO_ 2651591681 "Settings for  SCU system values (Settings for  SCU system values)";
CM_ SG_ 2651591681 SCU1_val_DamageResetMagic "Magic to set and reset system values. Has to be AA55AAh";
CM_ SG_ 2651591681 SCU1_val_ResetType "Counter which has to be reset:";
CM_ SG_ 2651591681 SCU1_conf_ResetValue "value to be specified as the set value";
CM_ SG_ 2651591681 SCU1_vrr_Day "value to be specified the day value of the RTC";
CM_ SG_ 2651591681 SCU1_vrr_Month "value to be specified the month value of the RTC";
CM_ SG_ 2651591681 SCU1_vrr_2kYear "value to be specified the 2kyear value of the RTC";
CM_ SG_ 2651591681 SCU1_vrr_Hour "value to be specified the hour value of the RTC";
CM_ SG_ 2651591681 SCU1_vrr_Minute "value to be specified the minute value of the RTC";
CM_ SG_ 2651591681 SCU1_vrr_Second "value to be specified the second value of the RTC";
CM_ BO_ 2449564673 "SCU operation time counter (SCU operation time counter)";
CM_ SG_ 2449564673 SCU1_ctr_t_AliveTime_s "Time the SCU has been powered up";
CM_ SG_ 2449564673 SCU1_ctr_t_OperationTime_s "Time in which the pos and neg contactors are closed";
CM_ BO_ 2449568769 "SCU usage counter (SCU usage counter)";
CM_ SG_ 2449568769 SCU1_ctr_Q_AmpereHourChg_Ah "alltime ampere hour counter charge";
CM_ SG_ 2449568769 SCU1_ctr_Q_AmpereHourDisch_Ah "alltime ampere hour counter discharge";
CM_ BO_ 2449576961 "SCU Histogramm (SCU Histogramm)";
CM_ SG_ 2449576961 SCU1_diag_HistMultiplex "Histogram multiplexer (see Comments)";
CM_ SG_ 2449576961 SCU1_diag_HistIndex "Index number";
CM_ SG_ 2449576961 SCU1_diag_HistIndexWert "Index value";
CM_ SG_ 2449576961 SCU1_diag_HistWerte "Histogram value";
CM_ BO_ 2449597441 "Real Time Clock values (Real Time Clock values)";
CM_ BO_ 2449536001 "SCU currents (SCU currents)";
CM_ SG_ 2449536001 SCU1_act_I_HVIL_mA "current of interlock loop";
CM_ SG_ 2449536001 SCU1_act_I_eStop_mA "current of eStop loop";
CM_ SG_ 2449536001 SCU1_act_I_CurrentSensTot_A "current sensor total (for multi current sensor systems)";
CM_ BO_ 2449548289 "SCU System Information (SCU System Information)";
CM_ BO_ 2449544193 "BMU serial numbers (BMU serial numbers)";
CM_ BO_ 2650801153 "acknowledge if SCU receives a downloader_magic (acknowledge if SCU receives a downloader_magic)";
CM_ SG_ 2650801153 SCU1_val_SerialNr "serial number";
CM_ SG_ 2650801153 SCU1_val_HWRev "HW revision";
CM_ BO_ 2650805249 "SCU software version number information (SCU software version number information)";
CM_ SG_ 2650805249 SCU1_val_SWVersionNr "software version number";
CM_ BO_ 2650813441 "Error_messages of SCU CAN bootloader (Error_messages of SCU CAN bootloader)";
CM_ SG_ 2650813441 SCU1_Error_Number "error number";
CM_ SG_ 2650813441 SCU1_Error_parameter_1 "error parameter 1";
CM_ SG_ 2650813441 SCU1_Error_parameter_2 "error parameter 2";
CM_ SG_ 2650813441 SCU1_subError_Number "suberror number";
CM_ BO_ 2650817537 "SCU configuration version number information (SCU configuration version number information)";
CM_ SG_ 2650817537 sw_version_nr "software version number";
CM_ BO_ 2650825729 "checksum of SCU software (checksum of SCU software)";
CM_ SG_ 2650825729 SCU1_sw_checksum "SCU software checksum";
CM_ SG_ 2650825729 SCU1_config_checksum "SCU config checksum";
CM_ BO_ 2650829825 "version datas of SCU CPU block 1 (version datas of SCU CPU block 1)";
CM_ SG_ 2650829825 SCU1_CPU_Version "version number of cpu";
CM_ SG_ 2650829825 SCU1_CPU_ModulNumber "modul number of cpu";
CM_ SG_ 2650829825 SCU1_CPU_DepartureNumber "departure number of cpu";
CM_ SG_ 2650829825 SCU1_CPU_ManufactureNumber "manufacture number of cpu";
CM_ SG_ 2650829825 SCU1_CPU_RevisionNumber "revision number of cpu";
CM_ SG_ 2650829825 SCU1_CPU_CHIPID "chip id of cpu";
CM_ BO_ 2650833921 "version datas of SCU CPU block 2 (version datas of SCU CPU block 2)";
CM_ SG_ 2650833921 SCU1_CPU_PROGVDD "version number of cpu";
CM_ SG_ 2650833921 SCU1_CPU_PROGVPP "modul number of cpu";
CM_ SG_ 2650833921 SCU1_CPU_MemSize "departure number of cpu";
CM_ SG_ 2650833921 SCU1_CPU_MemType "manufacture number of cpu";
CM_ BO_ 2650838017 "software component names (software component names)";
CM_ SG_ 2650838017 SCU1_ComponentNameActive "component name of the active boot loader component";
CM_ SG_ 2650838017 SCU1_DownloadComponentName "name of the component which will be downloaded";
CM_ BO_ 2650800129 "Information about actual  cell voltages (Information about actual  cell voltages)";
CM_ SG_ 2650800129 BMMp_max_U_CellVoltage_mV "highest actual measured cell voltage in system";
CM_ SG_ 2650800129 BMMp_min_U_CellVoltage_mV "lowest actual measured cell voltage in system";
CM_ SG_ 2650800129 BMMp_acg_U_CellVoltage_mV "average actual measured cell voltage in system";
CM_ SG_ 2650800129 BMMp_num_MaxCellVoltage "cell number of cell with actual highest voltage";
CM_ SG_ 2650800129 BMMp_num_MinCellVoltage "cell number of cell with actual lowest voltage";
CM_ BO_ 2650804225 "information about actual cell temperatures (information about actual cell temperatures)";
CM_ SG_ 2650804225 BMMp_max_T_CellTemp_C "highest actual measured cell temperature in system";
CM_ SG_ 2650804225 BMMp_min_T_CellTemp_C "lowest actual measured cell  temperature in system";
CM_ SG_ 2650804225 BMMp_avg_T_CellTemp_C "average actual measured cell  temperature in system";
CM_ SG_ 2650804225 BMMp_num_MaxCellTemp "cell number of cell with actual highest  temperature";
CM_ SG_ 2650804225 BMMp_num_MinCellTemp "cell number of cell with actual lowest  temperature";
CM_ BO_ 2650808321 "Byte 0   Byte 1   Byte 2   Byte 3   Byte 4   Byte 5   Byte 6   Byte 7";
CM_ SG_ 2650808321 BMMp_max_T_TerminalTemp_C "highest actual measured cell temperature in system";
CM_ SG_ 2650808321 BMMp_min_T_TerminalTemp_C "lowest actual measured cell  temperature in system";
CM_ SG_ 2650808321 BMMp_avg_T_TerminalTemp_C "average actual measured cell  temperature in system";
CM_ SG_ 2650808321 BMMp_num_MaxTerminalTemp "cell number of cell with actual highest  temperature";
CM_ SG_ 2650808321 BMMp_num_MinTerminalTemp "cell number of cell with actual lowest  temperature";
CM_ BO_ 2650812417 "Byte 0   Byte 1   Byte 2   Byte 3   Byte 4   Byte 5   Byte 6   Byte 7";
CM_ SG_ 2650812417 BMMp_act_I_BatteryCurrent_A "actual battery charge current";
CM_ SG_ 2650812417 BMMp_act_U_BatteryVoltage_V "actual battery voltage";
CM_ SG_ 2650812417 BMMp_act_P_BatteryPower_kW "actual battery power (current x voltage)";
CM_ SG_ 2650812417 BMMp_act_U_SystemVoltage_V "actual terminal voltage";
CM_ BO_ 2650816513 "Byte 0   Byte 1   Byte 2   Byte 3   Byte 4   Byte 5   Byte 6   Byte 7";
CM_ SG_ 2650816513 BMMp_flag_Wake "Ignition Pin set to high from VCU (drive request or charge request)";
CM_ SG_ 2650816513 BMMp_flag_ContactorHVPos "0 = contactor open; 1=contactor closed";
CM_ SG_ 2650816513 BMMp_flag_ContactorHVNeg "0 = contactor open; 1=contactor closed";
CM_ SG_ 2650816513 BMMp_flag_ContactorPrecha "0 = contactor open; 1=contactor closed";
CM_ SG_ 2650816513 BMMp_flag_ExternalSdwnRq "External request (CAN Rx Msg) to switch off battery";
CM_ SG_ 2650816513 BMMp_flag_InternalKL30Safe "internal KL30 set";
CM_ SG_ 2650816513 BMMp_flag_HVILState "High voltage interlock";
CM_ SG_ 2650816513 BMMp_cnt_MirroredAliveCounter "mirror of the received VCU alive counter";
CM_ BO_ 2650820609 "Byte 0   Byte 1   Byte 2   Byte 3   Byte 4   Byte 5   Byte 6   Byte 7";
CM_ BO_ 2650824705 "Byte 0   Byte 1   Byte 2   Byte 3   Byte 4   Byte 5   Byte 6   Byte 7";
CM_ SG_ 2650824705 BMMp_ef_InvalidData "short circuit or open temperature sensor";
CM_ SG_ 2650824705 BMMp_ef_ContactorWrongState "tbd";
CM_ SG_ 2650824705 BMMp_ef_CurrSens "i sensor error occurred";
CM_ SG_ 2650824705 BMMp_ef_ContDam "contactors damaged";
CM_ SG_ 2650824705 BMMp_ef_RefVoltErrorMax "refernce voltage to high";
CM_ SG_ 2650824705 BMMp_ef_RefVoltErrorMin "refernce voltage to low";
CM_ SG_ 2650824705 BMMp_ef_KL30SafeMax "KL30-Safe max";
CM_ SG_ 2650824705 BMMp_ef_KL30SafeMin "KL30-Safe min";
CM_ SG_ 2650824705 BMMp_ef_KL30SafeOff "BMS-M-SafePwr was switched off (HW detection)";
CM_ SG_ 2650824705 BMMp_ef_ContactorDropOut "a contactor drop out occured";
CM_ SG_ 2650824705 BMMp_ef_BoardTemp "ECU/IC board temperature too high/low";
CM_ BO_ 2650828801 "Byte 0   Byte 1   Byte 2   Byte 3   Byte 4   Byte 5   Byte 6   Byte 7";
CM_ SG_ 2650828801 BMMp_af_InvalidData "short circuit or open temperature sensor";
CM_ SG_ 2650828801 BMMp_af_ContactorWrongState "tbd";
CM_ SG_ 2650828801 BMMp_af_CurrSens "i sensor error occurred";
CM_ SG_ 2650828801 BMMp_af_ContDam "contactors damaged";
CM_ SG_ 2650828801 BMMp_af_RefVoltErrorMax "refernce voltage to high";
CM_ SG_ 2650828801 BMMp_af_RefVoltErrorMin "refernce voltage to low";
CM_ SG_ 2650828801 BMMp_af_KL30SafeMax "KL30-Safe max";
CM_ SG_ 2650828801 BMMp_af_KL30SafeMin "KL30-Safe min";
CM_ SG_ 2650828801 BMMp_af_KL30SafeOff "BMS-M-SafePwr was switched off (HW detection)";
CM_ SG_ 2650828801 BMMp_af_ContactorDropOut "a contactor drop out occured";
CM_ SG_ 2650828801 BMMp_af_BoardTemp "ECU/IC board temperature too high/low";
CM_ BO_ 2650832897 "Byte 0   Byte 1   Byte 2   Byte 3   Byte 4   Byte 5   Byte 6   Byte 7";
CM_ SG_ 2650832897 BMMp_wf_InvalidData "short circuit or open temperature sensor";
CM_ SG_ 2650832897 BMMp_wf_ContactorWrongState "tbd";
CM_ SG_ 2650832897 BMMp_wf_CurrSens "i sensor error occurred";
CM_ SG_ 2650832897 BMMp_wf_ContDam "contactors damaged";
CM_ SG_ 2650832897 BMMp_wf_RefVoltErrorMax "refernce voltage to high";
CM_ SG_ 2650832897 BMMp_wf_RefVoltErrorMin "refernce voltage to low";
CM_ SG_ 2650832897 BMMp_wf_KL30SafeMax "KL30-Safe max";
CM_ SG_ 2650832897 BMMp_wf_KL30SafeMin "KL30-Safe min";
CM_ SG_ 2650832897 BMMp_wf_KL30SafeOff "BMS-M-SafePwr was switched off (HW detection)";
CM_ SG_ 2650832897 BMMp_wf_ContactorDropOut "a contactor drop out occured";
CM_ SG_ 2650832897 BMMp_wf_BoardTemp "ECU/IC board temperature too high/low";
CM_ BO_ 2650836993 "Byte 0   Byte 1   Byte 2   Byte 3   Byte 4   Byte 5   Byte 6   Byte 7";
CM_ SG_ 2650836993 BMMp_num_Errorvalue "additional information in case of an active warning/alarm/error (value that caused the warning/alarm/error)";
CM_ SG_ 2650836993 BMMp_num_ErrSrcCompNr "Error source component number";
CM_ SG_ 2650836993 BMMp_num_ErrSrcSubcompClass "Error source subcomponent class";
CM_ SG_ 2650836993 BMMp_num_ErrSrcCompClass "Error source component class";
CM_ SG_ 2650836993 BMMp_num_Errornumber "number of the active warning/alarm/error";
CM_ SG_ 2650836993 BMMp_num_ErrDetectDevice "error dectecting device number";
CM_ BO_ 2650841089 "Byte 0   Byte 1   Byte 2   Byte 3   Byte 4   Byte 5   Byte 6   Byte 7";
CM_ BO_ 2650845185 "Byte 0   Byte 1   Byte 2   Byte 3   Byte 4   Byte 5   Byte 6   Byte 7";
CM_ SG_ 2650845185 BMMp_lim_regenPower_W "maximum permitted regen power";
CM_ SG_ 2650845185 BMMp_lim_I_regenCurr_A "maximum permitted regen current";
CM_ SG_ 2650845185 BMMp_lim_I_ChargeCurr_A "maximum permitted charge current";
CM_ SG_ 2650845185 BMMp_lim_I_DischargeCurr_A "maximum permitted discharge current";
CM_ BO_ 2650849281 "Byte 0   Byte 1   Byte 2   Byte 3   Byte 4   Byte 5   Byte 6   Byte 7";
CM_ SG_ 2650849281 BMMp_lim_U_MaxVolt_V "maximum permitted voltage limit for battery";
CM_ SG_ 2650849281 BMMp_lim_U_MinVolt_V "minimum permitted voltage limit for battery";
CM_ SG_ 2650849281 BMMp_lim_P_ChargePow_W "maximum permitted charge power";
CM_ SG_ 2650849281 BMMp_lim_P_DischargePow_W "maximum permitted discharge power";
CM_ BO_ 2650853377 "Byte 0   Byte 1   Byte 2   Byte 3   Byte 4   Byte 5   Byte 6   Byte 7";
CM_ BO_ 2650857473 "Byte 0   Byte 1   Byte 2   Byte 3   Byte 4   Byte 5   Byte 6   Byte 7";
CM_ SG_ 2650857473 BMMp_calc_SOHcapacity_pct "Internal SoH (actual SoH capacity)";
CM_ BO_ 2650861569 "Byte 0   Byte 1   Byte 2   Byte 3   Byte 4   Byte 5   Byte 6   Byte 7";
CM_ BO_ 2650865665 "Byte 0   Byte 1   Byte 2   Byte 3   Byte 4   Byte 5   Byte 6   Byte 7";
CM_ SG_ 2650865665 BMMp_req_T_InletTemp_C "Requested Inlet Temperature";
CM_ SG_ 2650865665 BMMp_req_Mode "Signal for TCU that determines the mode, the TCU should work with";
CM_ SG_ 2650865665 BMMp_avg_T_BatteryTemp_C "Average Cell Temperature";
CM_ SG_ 2650865665 BMMp_req_Heater_pct "desired heater power in percent";
CM_ SG_ 2650865665 BMMp_req_Chiller_pct "desired chiller power in percent";
CM_ BO_ 2650869761 "Byte 0   Byte 1   Byte 2   Byte 3   Byte 4   Byte 5   Byte 6   Byte 7";
CM_ BO_ 2650873857 "Byte 0   Byte 1   Byte 2   Byte 3   Byte 4   Byte 5   Byte 6   Byte 7";
CM_ BO_ 2650877953 "Byte 0   Byte 1   Byte 2   Byte 3   Byte 4   Byte 5   Byte 6   Byte 7";
CM_ BO_ 2650882049 "Byte 0   Byte 1   Byte 2   Byte 3   Byte 4   Byte 5   Byte 6   Byte 7";
CM_ BO_ 2650886145 "Byte 0   Byte 1   Byte 2   Byte 3   Byte 4   Byte 5   Byte 6   Byte 7";
CM_ BO_ 2650890241 "Byte 0   Byte 1   Byte 2   Byte 3   Byte 4   Byte 5   Byte 6   Byte 7";
CM_ BO_ 2650894337 "Byte 0   Byte 1   Byte 2   Byte 3   Byte 4   Byte 5   Byte 6   Byte 7";
CM_ BO_ 2650898433 "Byte 0   Byte 1   Byte 2   Byte 3   Byte 4   Byte 5   Byte 6   Byte 7";
CM_ BO_ 2650902529 "Byte 0   Byte 1   Byte 2   Byte 3   Byte 4   Byte 5   Byte 6   Byte 7";
CM_ BO_ 2650906625 "Byte 0   Byte 1   Byte 2   Byte 3   Byte 4   Byte 5   Byte 6   Byte 7";
CM_ BO_ 2650914817 "Byte 0   Byte 1   Byte 2   Byte 3   Byte 4   Byte 5   Byte 6   Byte 7";
CM_ BO_ 2651161601 "Byte 0   Byte 1   Byte 2   Byte 3   Byte 4   Byte 5   Byte 6   Byte 7";
CM_ BO_ 2651165697 "Byte 0   Byte 1   Byte 2   Byte 3   Byte 4   Byte 5   Byte 6   Byte 7";
CM_ BO_ 2651169793 "Byte 0   Byte 1   Byte 2   Byte 3   Byte 4   Byte 5   Byte 6   Byte 7";
CM_ BO_ 2651173889 "Byte 0   Byte 1   Byte 2   Byte 3   Byte 4   Byte 5   Byte 6   Byte 7";
CM_ BO_ 2651182081 "Byte 0   Byte 1   Byte 2   Byte 3   Byte 4   Byte 5   Byte 6   Byte 7";
CM_ BO_ 2651186177 "Byte 0   Byte 1   Byte 2   Byte 3   Byte 4   Byte 5   Byte 6   Byte 7";
CM_ BO_ 2651190273 "Byte 0   Byte 1   Byte 2   Byte 3   Byte 4   Byte 5   Byte 6   Byte 7";
CM_ BO_ 2449585153 "Byte 0   Byte 1   Byte 2   Byte 3   Byte 4   Byte 5   Byte 6   Byte 7";
CM_ BO_ 2449589249 "Byte 0   Byte 1   Byte 2   Byte 3   Byte 4   Byte 5   Byte 6   Byte 7";
CM_ BO_ 2449593345 "Byte 0   Byte 1   Byte 2   Byte 3   Byte 4   Byte 5   Byte 6   Byte 7";
CM_ BO_ 2651331585 "Information about cell voltages an temperature (Information about cell voltages an temperature)";
CM_ SG_ 2651331585 V001_set_U_CellVoltage_mV "set cell voltage";
CM_ SG_ 2651331585 T001_set_T_CellTemp_C "set cell temperature";
CM_ SG_ 2651331585 V001_set_U_GPIOVoltage_mV "only EOL: set GPIO voltage to corresponding cell temperature";
CM_ BO_ 2651331586 "Information about cell voltages an temperature (Information about cell voltages an temperature)";
CM_ SG_ 2651331586 V002_set_U_CellVoltage_mV "set cell voltage";
CM_ SG_ 2651331586 T002_set_T_CellTemp_C "set cell temperature";
CM_ SG_ 2651331586 V002_set_U_GPIOVoltage_mV "only EOL: set GPIO voltage to corresponding cell temperature";
CM_ BO_ 2651331587 "Information about cell voltages an temperature (Information about cell voltages an temperature)";
CM_ SG_ 2651331587 V003_set_U_CellVoltage_mV "set cell voltage";
CM_ SG_ 2651331587 T003_set_T_CellTemp_C "set cell temperature";
CM_ SG_ 2651331587 V003_set_U_GPIOVoltage_mV "only EOL: set GPIO voltage to corresponding cell temperature";
CM_ BO_ 2651331588 "Information about cell voltages an temperature (Information about cell voltages an temperature)";
CM_ SG_ 2651331588 V004_set_U_CellVoltage_mV "set cell voltage";
CM_ SG_ 2651331588 T004_set_T_CellTemp_C "set cell temperature";
CM_ SG_ 2651331588 V004_set_U_GPIOVoltage_mV "only EOL: set GPIO voltage to corresponding cell temperature";
CM_ BO_ 2651331589 "Information about cell voltages an temperature (Information about cell voltages an temperature)";
CM_ SG_ 2651331589 V005_set_U_CellVoltage_mV "set cell voltage";
CM_ SG_ 2651331589 T005_set_T_CellTemp_C "set cell temperature";
CM_ SG_ 2651331589 V005_set_U_GPIOVoltage_mV "only EOL: set GPIO voltage to corresponding cell temperature";
CM_ BO_ 2651331590 "Information about cell voltages an temperature (Information about cell voltages an temperature)";
CM_ SG_ 2651331590 V006_set_U_CellVoltage_mV "set cell voltage";
CM_ SG_ 2651331590 T006_set_T_CellTemp_C "set cell temperature";
CM_ SG_ 2651331590 V006_set_U_GPIOVoltage_mV "only EOL: set GPIO voltage to corresponding cell temperature";
CM_ BO_ 2651331591 "Information about cell voltages an temperature (Information about cell voltages an temperature)";
CM_ SG_ 2651331591 V007_set_U_CellVoltage_mV "set cell voltage";
CM_ SG_ 2651331591 T007_set_T_CellTemp_C "set cell temperature";
CM_ SG_ 2651331591 V007_set_U_GPIOVoltage_mV "only EOL: set GPIO voltage to corresponding cell temperature";
CM_ BO_ 2651331592 "Information about cell voltages an temperature (Information about cell voltages an temperature)";
CM_ SG_ 2651331592 V008_set_U_CellVoltage_mV "set cell voltage";
CM_ SG_ 2651331592 T008_set_T_CellTemp_C "set cell temperature";
CM_ SG_ 2651331592 V008_set_U_GPIOVoltage_mV "only EOL: set GPIO voltage to corresponding cell temperature";
CM_ BO_ 2651331593 "Information about cell voltages an temperature (Information about cell voltages an temperature)";
CM_ SG_ 2651331593 V009_set_U_CellVoltage_mV "set cell voltage";
CM_ SG_ 2651331593 T009_set_T_CellTemp_C "set cell temperature";
CM_ SG_ 2651331593 V009_set_U_GPIOVoltage_mV "only EOL: set GPIO voltage to corresponding cell temperature";
CM_ BO_ 2651331594 "Information about cell voltages an temperature (Information about cell voltages an temperature)";
CM_ SG_ 2651331594 V010_set_U_CellVoltage_mV "set cell voltage";
CM_ SG_ 2651331594 T010_set_T_CellTemp_C "set cell temperature";
CM_ SG_ 2651331594 V010_set_U_GPIOVoltage_mV "only EOL: set GPIO voltage to corresponding cell temperature";
CM_ BO_ 2651331595 "Information about cell voltages an temperature (Information about cell voltages an temperature)";
CM_ SG_ 2651331595 V011_set_U_CellVoltage_mV "set cell voltage";
CM_ SG_ 2651331595 T011_set_T_CellTemp_C "set cell temperature";
CM_ SG_ 2651331595 V011_set_U_GPIOVoltage_mV "only EOL: set GPIO voltage to corresponding cell temperature";
CM_ BO_ 2651331596 "Information about cell voltages an temperature (Information about cell voltages an temperature)";
CM_ SG_ 2651331596 V012_set_U_CellVoltage_mV "set cell voltage";
CM_ SG_ 2651331596 T012_set_T_CellTemp_C "set cell temperature";
CM_ SG_ 2651331596 V012_set_U_GPIOVoltage_mV "only EOL: set GPIO voltage to corresponding cell temperature";
CM_ BO_ 2651331597 "Information about cell voltages an temperature (Information about cell voltages an temperature)";
CM_ SG_ 2651331597 V013_set_U_CellVoltage_mV "set cell voltage";
CM_ SG_ 2651331597 T013_set_T_CellTemp_C "set cell temperature";
CM_ SG_ 2651331597 V013_set_U_GPIOVoltage_mV "only EOL: set GPIO voltage to corresponding cell temperature";
CM_ BO_ 2651331598 "Information about cell voltages an temperature (Information about cell voltages an temperature)";
CM_ SG_ 2651331598 V014_set_U_CellVoltage_mV "set cell voltage";
CM_ SG_ 2651331598 T014_set_T_CellTemp_C "set cell temperature";
CM_ SG_ 2651331598 V014_set_U_GPIOVoltage_mV "only EOL: set GPIO voltage to corresponding cell temperature";
CM_ BO_ 2651331599 "Information about cell voltages an temperature (Information about cell voltages an temperature)";
CM_ SG_ 2651331599 V015_set_U_CellVoltage_mV "set cell voltage";
CM_ SG_ 2651331599 T015_set_T_CellTemp_C "set cell temperature";
CM_ SG_ 2651331599 V015_set_U_GPIOVoltage_mV "only EOL: set GPIO voltage to corresponding cell temperature";
CM_ BO_ 2651331600 "Information about cell voltages an temperature (Information about cell voltages an temperature)";
CM_ SG_ 2651331600 V016_set_U_CellVoltage_mV "set cell voltage";
CM_ SG_ 2651331600 T016_set_T_CellTemp_C "set cell temperature";
CM_ SG_ 2651331600 V016_set_U_GPIOVoltage_mV "only EOL: set GPIO voltage to corresponding cell temperature";
CM_ BO_ 2651331601 "Information about cell voltages an temperature (Information about cell voltages an temperature)";
CM_ SG_ 2651331601 V017_set_U_CellVoltage_mV "set cell voltage";
CM_ SG_ 2651331601 T017_set_T_CellTemp_C "set cell temperature";
CM_ SG_ 2651331601 V017_set_U_GPIOVoltage_mV "only EOL: set GPIO voltage to corresponding cell temperature";
CM_ BO_ 2651331602 "Information about cell voltages an temperature (Information about cell voltages an temperature)";
CM_ SG_ 2651331602 V018_set_U_CellVoltage_mV "set cell voltage";
CM_ SG_ 2651331602 T018_set_T_CellTemp_C "set cell temperature";
CM_ SG_ 2651331602 V018_set_U_GPIOVoltage_mV "only EOL: set GPIO voltage to corresponding cell temperature";
CM_ BO_ 2651331603 "Information about cell voltages an temperature (Information about cell voltages an temperature)";
CM_ SG_ 2651331603 V019_set_U_CellVoltage_mV "set cell voltage";
CM_ SG_ 2651331603 T019_set_T_CellTemp_C "set cell temperature";
CM_ SG_ 2651331603 V019_set_U_GPIOVoltage_mV "only EOL: set GPIO voltage to corresponding cell temperature";
CM_ BO_ 2651331604 "Information about cell voltages an temperature (Information about cell voltages an temperature)";
CM_ SG_ 2651331604 V020_set_U_CellVoltage_mV "set cell voltage";
CM_ SG_ 2651331604 T020_set_T_CellTemp_C "set cell temperature";
CM_ SG_ 2651331604 V020_set_U_GPIOVoltage_mV "only EOL: set GPIO voltage to corresponding cell temperature";
CM_ BO_ 2651404289 "Write Data to the emulated EEPROM (Write Data to the emulated EEPROM)";
CM_ SG_ 2651404289 M001_val_EEPROMWriteLength "Length of EEPROM Data";
CM_ SG_ 2651404289 M001_val_EEPROMWriteIndex "Index of EEPROM Data";
CM_ SG_ 2651404289 M001_val_EEPROMWriteAdress "Adress of EEPROM Data";
CM_ SG_ 2651404289 M001_val_EEPROMWriteData "EEPROM write data";
CM_ BO_ 2651404545 "Read Data from the emulated EEPROM (Read Data from the emulated EEPROM)";
CM_ SG_ 2651404545 M001_ReadEEPROMData_LTC_Mux "Bit[6:4] Area, Bit[3:0] Index";
CM_ SG_ 2651404545 M001_val_EEPROMWriteArea "Area of EEPROM Data:  0: Id Area, 1 Static, 2: Dynamic, 4: ID Copy, 5, Static Copy:6:Dynamic Copy";
CM_ SG_ 2651404545 M001_val_EEPROMWriteAdress "Index of EEPROM Data";
CM_ SG_ 2651404545 M001_val_EEPROMWriteData "EEPROM read data";
BA_DEF_ BO_  "GenMsgCycleTime" INT 0 65535;
BA_DEF_ SG_  "GenSigStartValue" FLOAT -3.4E+038 3.4E+038;
BA_DEF_DEF_  "GenMsgCycleTime" 0;
BA_DEF_DEF_  "GenSigStartValue" 0;
BA_ "GenMsgCycleTime" BO_ 2449527809 100;
BA_ "GenMsgCycleTime" BO_ 2316833792 40;
BA_ "GenMsgCycleTime" BO_ 2651595777 1000;
BA_ "GenMsgCycleTime" BO_ 2449540097 1000;
BA_ "GenMsgCycleTime" BO_ 2449552385 1000;
BA_ "GenMsgCycleTime" BO_ 2449556481 1000;
BA_ "GenMsgCycleTime" BO_ 2348811265 100;
BA_ "GenMsgCycleTime" BO_ 2651067393 1000;
BA_ "GenMsgCycleTime" BO_ 2651071489 1000;
BA_ "GenMsgCycleTime" BO_ 2651075585 1000;
BA_ "GenMsgCycleTime" BO_ 2651079681 1000;
BA_ "GenMsgCycleTime" BO_ 2651083777 1000;
BA_ "GenMsgCycleTime" BO_ 2651087873 1000;
BA_ "GenMsgCycleTime" BO_ 2651091969 1000;
BA_ "GenMsgCycleTime" BO_ 2651096065 1000;
BA_ "GenMsgCycleTime" BO_ 2651100161 1000;
BA_ "GenMsgCycleTime" BO_ 2651104257 1000;
BA_ "GenMsgCycleTime" BO_ 2651063297 1000;
BA_ "GenMsgCycleTime" BO_ 2181563392 2000;
BA_ "GenMsgCycleTime" BO_ 2315342849 100;
BA_ "GenMsgCycleTime" BO_ 2449564673 1000;
BA_ "GenMsgCycleTime" BO_ 2449568769 1000;
BA_ "GenMsgCycleTime" BO_ 2449576961 1000;
BA_ "GenMsgCycleTime" BO_ 2449597441 100;
BA_ "GenMsgCycleTime" BO_ 2449536001 100;
BA_ "GenMsgCycleTime" BO_ 2449548289 1000;
BA_ "GenMsgCycleTime" BO_ 2449544193 1000;
BA_ "GenMsgCycleTime" BO_ 2650804225 500;
BA_ "GenMsgCycleTime" BO_ 2650808321 500;
BA_ "GenMsgCycleTime" BO_ 2650812417 100;
BA_ "GenMsgCycleTime" BO_ 2650845185 100;
BA_ "GenMsgCycleTime" BO_ 2650849281 100;
BA_ "GenMsgCycleTime" BO_ 2650853377 100;
BA_ "GenMsgCycleTime" BO_ 2650857473 500;
BA_ "GenMsgCycleTime" BO_ 2650861569 100;
BA_ "GenMsgCycleTime" BO_ 2650873857 1000;
BA_ "GenMsgCycleTime" BO_ 2650898433 100;
BA_ "GenMsgCycleTime" BO_ 2650906625 1000;
VAL_ 2449548289 SCU1_SysInfo_Mux 0 "SCU1_inf_SysInfoCPUBoardId" 1 "SCU1_inf_SysInfoMuxHVBoardId" 2 "SCU1_inf_SysInfoBBoardId" 3 "SCU1_inf_SysInfoMRCCBBoardId" 4 "SCU1_inf_SysInfoHwRev" 5 "SCU1_inf_SysInfoMCU";
VAL_ 2449544193 SCU1_AkaSerialNo_Mux 0 "Production" 1 "Electronics" 3 "Software";
VAL_ 2651404545 M001_ReadEEPROMData_LTC_Mux 255 "M001_val_EEPROMDataIndex";
VAL_ 2449527809 SCU1_af_CellVoltageMax 0 "no" 1 "yes";
VAL_ 2449527809 SCU1_af_CellVoltageMin 0 "no" 1 "yes";
VAL_ 2449527809 SCU1_af_SysVoltageMax 0 "no" 1 "yes";
VAL_ 2449527809 SCU1_af_SysVoltageMin 0 "no" 1 "yes";
VAL_ 2449527809 SCU1_af_SysVoltageSum 0 "no" 1 "yes";
VAL_ 2449527809 SCU1_af_ModVoltageSum 0 "no" 1 "yes";
VAL_ 2449527809 SCU1_af_ModVoltageRefMax 0 "no" 1 "yes";
VAL_ 2449527809 SCU1_af_Mod_Voltage_Ref_Min 0 "no" 1 "yes";
VAL_ 2449527809 SCU1_af_IsoFaultBattNeg 0 "no" 1 "yes";
VAL_ 2449527809 SCU1_af_IsoFaultBattPos 0 "no" 1 "yes";
VAL_ 2449527809 SCU1_af_ContactorNegStuck 0 "no" 1 "yes";
VAL_ 2449527809 SCU1_af_ContactorPosStuck 0 "no" 1 "yes";
VAL_ 2449527809 SCU1_af_LVSupplyMax 0 "no" 1 "yes";
VAL_ 2449527809 SCU1_af_LVSupplyMin 0 "no" 1 "yes";
VAL_ 2449527809 SCU1_af_TerminalTempMax 0 "no" 1 "yes";
VAL_ 2449527809 SCU1_af_TerminalTempMin 0 "no" 1 "yes";
VAL_ 2449527809 SCU1_af_CellTempChargMax 0 "no" 1 "yes";
VAL_ 2449527809 SCU1_af_CellTempChargMin 0 "no" 1 "yes";
VAL_ 2449527809 SCU1_af_CellTempDischMax 0 "no" 1 "yes";
VAL_ 2449527809 SCU1_af_CellTempDischMin 0 "no" 1 "yes";
VAL_ 2449527809 SCU1_af_SysCurCha 0 "no" 1 "yes";
VAL_ 2449527809 SCU1_af_SysCurDis 0 "no" 1 "yes";
VAL_ 2449527809 SCU1_af_HVCurrLoopMax 0 "no" 1 "yes";
VAL_ 2449527809 SCU1_af_HVCurrLoopMin 0 "no" 1 "yes";
VAL_ 2449527809 SCU1_af_eStopCurrLoopMax 0 "no" 1 "yes";
VAL_ 2449527809 SCU1_af_eStopCurrLoopMin 0 "no" 1 "yes";
VAL_ 2449527809 SCU1_af_SysCurLimitCha 0 "no" 1 "yes";
VAL_ 2449527809 SCU1_af_SysCurLimitDis 0 "no" 1 "yes";
VAL_ 2449527809 SCU1_af_SysPrechargeFailed 0 "no" 1 "yes";
VAL_ 2449527809 SCU1_af_BMMBattCom 0 "no" 1 "yes";
VAL_ 2449527809 SCU1_af_SysInitTimeout 0 "no" 1 "yes";
VAL_ 2449527809 SCU1_af_SCUConfig 0 "no" 1 "yes";
VAL_ 2449527809 SCU1_af_DeepDischProt 0 "no" 1 "yes";
VAL_ 2449527809 SCU1_af_WDReset 0 "no" 1 "yes";
VAL_ 2449527809 SCU1_af_ExtCommunicationTout 0 "no" 1 "yes";
VAL_ 2449527809 SCU1_af_NoAfterrunTest 0 "no" 1 "yes";
VAL_ 2449527809 SCU1_af_CellVoltUnbalance 0 "no" 1 "yes";
VAL_ 2449527809 SCU1_af_CellTempUnbalance 0 "no" 1 "yes";
VAL_ 2449527809 SCU1_af_TerminalTempUnbalance 0 "no" 1 "yes";
VAL_ 2449527809 SCU1_af_LTCError 0 "no" 1 "yes";
VAL_ 2449527809 SCU1_af_AfterrunTest 0 "no" 1 "yes";
VAL_ 2449527809 SCU1_af_CrossCheck 0 "no" 1 "yes";
VAL_ 2449527809 SCU1_af_StuckAtTemp 0 "no" 1 "yes";
VAL_ 2449527809 SCU1_af_StuckAtVolt 0 "no" 1 "yes";
VAL_ 2449527809 SCU1_af_ProgProcess 0 "no" 1 "yes";
VAL_ 2449527809 SCU1_af_RAM 0 "no" 1 "yes";
VAL_ 2449527809 SCU1_af_ROM 0 "no" 1 "yes";
VAL_ 2449527809 SCU1_af_FlashEEPROM 0 "no" 1 "yes";
VAL_ 2449527809 SCU1_af_InvalidData 0 "no" 1 "yes";
VAL_ 2449527809 SCU1_af_ContactorWrongState 0 "no" 1 "yes";
VAL_ 2449527809 SCU1_af_CurrSens 0 "no" 1 "yes";
VAL_ 2449527809 SCU1_af_ContDam 0 "no" 1 "yes";
VAL_ 2449527809 SCU1_af_RefVoltErrorMax 0 "no" 1 "yes";
VAL_ 2449527809 SCU1_af_RefVoltErrorMin 0 "no" 1 "yes";
VAL_ 2449527809 SCU1_af_KL30SafeMax 0 "no" 1 "yes";
VAL_ 2449527809 SCU1_af_KL30SafeMin 0 "no" 1 "yes";
VAL_ 2449527809 SCU1_af_CPUSupplyWarning 0 "no" 1 "yes";
VAL_ 2449527809 SCU1_af_PowerProtectionWarning 0 "no" 1 "yes";
VAL_ 2449527809 SCU1_af_KL30SafeOff 0 "no" 1 "yes";
VAL_ 2449527809 SCU1_af_Dew_Sensor 0 "no" 1 "yes";
VAL_ 2449527809 SCU1_af_ContactorDropOut 0 "no" 1 "yes";
VAL_ 2449527809 SCU1_af_BoardTemp 0 "no" 1 "yes";
VAL_ 2449527809 SCU1_af_SCUError 0 "no" 1 "yes";
VAL_ 2316833792 BMM_req_ContactorPos 0 "off" 1 "on";
VAL_ 2316833792 BMM_req_ContactorNeg 0 "off" 1 "on";
VAL_ 2316833792 BMM_req_ContactorPre 0 "off" 1 "on";
VAL_ 2316833792 BMM_req_ContactorAux 0 "off" 1 "on";
VAL_ 2316833792 BMM_req_VSenseRelayBatPos 0 "off" 1 "on";
VAL_ 2316833792 BMM_req_VSenseRelayBatNeg 0 "off" 1 "on";
VAL_ 2316833792 BMM_req_VSenseRelaySysPos 0 "off" 1 "on";
VAL_ 2316833792 BMM_req_VSenseRelaySysNeg 0 "off" 1 "on";
VAL_ 2316833792 BMM_Fan_State 0 "off" 1 "on";
VAL_ 2651595777 SCU1_req_ContactorPosDiag 0 "off" 1 "on";
VAL_ 2651595777 SCU1_req_ContactorNegDiag 0 "off" 1 "on";
VAL_ 2651595777 SCU1_req_ContactorPreDiag 0 "off" 1 "on";
VAL_ 2651595777 SCU1_req_ContactorAuxDiag 0 "off" 1 "on";
VAL_ 2651595777 SCU1_req_VSenseRelayBatPosDiag 0 "off" 1 "on";
VAL_ 2651595777 SCU1_req_VSenseRelayBatNegDiag 0 "off" 1 "on";
VAL_ 2651595777 SCU1_req_VSenseRelaySysPosDiag 0 "off" 1 "on";
VAL_ 2651595777 SCU1_req_VSenseRelaySysNegDiag 0 "off" 1 "on";
VAL_ 2651595777 SCU1_req_ShutdownDiag 0 "off" 1 "on";
VAL_ 2651595777 SCU1_req_CANGatewayDiag 0 "off" 1 "on";
VAL_ 2651595777 SCU1_req_eStopBrakeOutDiag 0 "eStop loop closed" 1 "eStop brake out";
VAL_ 2651595777 SCU1_req_InterlockSourceDiag 0 "off" 1 "on";
VAL_ 2651595777 SCU1_req_WdgTrigOffDiag 0 "normal watchdog trigger" 1 "no wachdog trigger";
VAL_ 2651595777 SCU1_req_SafetyEnable1Diag 0 "off" 1 "on";
VAL_ 2651595777 SCU1_req_SafetyEnable2Diag 0 "off" 1 "on";
VAL_ 2651595777 SCU1_req_BMSPowerDiag 0 "off" 1 "on";
VAL_ 2651595777 SCU1_req_SystemResetDiag 0 "no reset" 1 "reset";
VAL_ 2651595777 SCU1_req_WdgTrigFastDiag 0 "normal watchdog trigger" 1 "fast watchdog trigger";
VAL_ 2651595777 SCU1_req_WdgAlarmResetDiag 0 "trigger internal watchdog" 1 "no internal watchdog trigger";
VAL_ 2651100161 SCU1_raw_DIO_P02_00_In 0 "Hi" 1 "Lo";
VAL_ 2651100161 SCU1_raw_DIO_P02_01_In 0 "Lo" 1 "Hi";
VAL_ 2651100161 SCU1_raw_DIO_P02_02_In 0 "Lo" 1 "Hi";
VAL_ 2651100161 SCU1_raw_DIO_P02_05_Out 0 "Hi" 1 "Lo";
VAL_ 2651100161 SCU1_raw_DIO_P02_06_In 0 "Hi" 1 "Lo";
VAL_ 2651100161 SCU1_raw_DIO_P02_07_In 0 "Lo" 1 "Hi";
VAL_ 2651100161 SCU1_raw_DIO_P02_12_Out 0 "Lo" 1 "Hi";
VAL_ 2651100161 SCU1_raw_DIO_P03_03_Out 0 "Lo" 1 "Hi";
VAL_ 2651100161 SCU1_raw_DIO_P03_04_Out 0 "Lo" 1 "Hi";
VAL_ 2651100161 SCU1_raw_DIO_P04_04_Out 0 "Lo" 1 "Hi";
VAL_ 2651100161 SCU1_raw_DIO_P04_05_Out 0 "Lo" 1 "Hi";
VAL_ 2651100161 SCU1_raw_DIO_P04_06_Out 0 "Lo" 1 "Hi";
VAL_ 2651100161 SCU1_raw_DIO_P04_07_Out 0 "Lo" 1 "Hi";
VAL_ 2651100161 SCU1_raw_DIO_P06_02_Out 0 "Lo" 1 "Hi";
VAL_ 2651100161 SCU1_raw_DIO_P06_03_Out 0 "Lo" 1 "Hi";
VAL_ 2651100161 SCU1_raw_DIO_P07_01_Out 0 "Hi" 1 "Lo";
VAL_ 2651100161 SCU1_raw_DIO_P07_02_Out 0 "Lo" 1 "Hi";
VAL_ 2651100161 SCU1_raw_DIO_P08_03_Out 0 "Lo" 1 "Hi";
VAL_ 2651100161 SCU1_raw_DIO_P08_04_Out 0 "Lo" 1 "Hi";
VAL_ 2651100161 SCU1_raw_DIO_P08_05_Out 0 "Lo" 1 "Hi";
VAL_ 2651100161 SCU1_raw_DIO_P08_06_Out 0 "Lo" 1 "Hi";
VAL_ 2651100161 SCU1_raw_DIO_P09_00_BiIO 0 "Lo" 1 "Hi";
VAL_ 2651100161 SCU1_raw_DIO_P09_01_Out 0 "Lo" 1 "Hi";
VAL_ 2651100161 SCU1_raw_DIO_P09_02_Out 0 "Lo" 1 "Hi";
VAL_ 2651100161 SCU1_raw_DIO_P09_03_Out 0 "Lo" 1 "Hi";
VAL_ 2651100161 SCU1_raw_DIO_P09_04_Out 0 "Lo" 1 "Hi";
VAL_ 2651100161 SCU1_raw_DIO_P09_05_BiIO 0 "Lo" 1 "Hi";
VAL_ 2651100161 SCU1_raw_DIO_P09_06_BiIO 0 "Lo" 1 "Hi";
VAL_ 2651100161 SCU1_raw_DIO_P09_07_BiIO 0 "Lo" 1 "Hi";
VAL_ 2651100161 SCU1_raw_DIO_P10_08_BiIO 0 "Lo" 1 "Hi";
VAL_ 2651100161 SCU1_raw_DIO_P10_09_BiIO 0 "Lo" 1 "Hi";
VAL_ 2651100161 SCU1_raw_DIO_P10_10_Out 0 "Lo" 1 "Hi";
VAL_ 2651100161 SCU1_raw_DIO_P10_11_Out 0 "Lo" 1 "Hi";
VAL_ 2651100161 SCU1_raw_DIO_P10_12_Out 0 "Lo" 1 "Hi";
VAL_ 2651100161 SCU1_raw_DIO_P11_02_Out 0 "Lo" 1 "Hi";
VAL_ 2651100161 SCU1_raw_DIO_P11_03_Out 0 "Lo" 1 "Hi";
VAL_ 2651100161 SCU1_raw_DIO_P11_04_Out 0 "Lo" 1 "Hi";
VAL_ 2651100161 SCU1_raw_DIO_P11_05_Out 0 "Hi" 1 "Lo";
VAL_ 2651100161 SCU1_raw_DIO_ESR0_In 0 "Lo" 1 "Hi";
VAL_ 2651100161 SCU1_raw_DIO_ESR1_In 0 "Lo" 1 "Hi";
VAL_ 2651100161 SCU1_raw_DIO_ESR2_In 0 "Lo" 1 "Hi";
VAL_ 2651104257 SCU1_raw_ID_bit_0 0 "not connected 1";
VAL_ 2651104257 SCU1_raw_ID_bit_1 0 "not connected 1";
VAL_ 2651104257 SCU1_raw_ID_bit_2 0 "not connected 1";
VAL_ 2651104257 SCU1_raw_ID_bit_3 0 "not connected 1";
VAL_ 2651104257 SCU1_raw_ID_bit_4 0 "not connected 1";
VAL_ 2651104257 SCU1_raw_Watchdog_Alarm_bit_0 0 "no watchdog" 1 "watchdog recognized";
VAL_ 2651104257 SCU1_raw_Watchdog_Alarm_bit_1 0 "no watchdog" 1 "watchdog recognized";
VAL_ 2650816513 BMMp_flag_Wake 0 "off" 1 "on";
VAL_ 2650816513 BMMp_flag_IsoDisable 0 "no" 1 "yes";
VAL_ 2650816513 BMMp_flag_ContactorHVPos 0 "off" 1 "on";
VAL_ 2650816513 BMMp_flag_ContactorHVNeg 0 "off" 1 "on";
VAL_ 2650816513 BMMp_flag_ContactorPrecha 0 "off" 1 "on";
VAL_ 2650816513 BMMp_flag_ChargeComplete 0 "no" 1 "yes";
VAL_ 2650816513 BMMp_flag_ExternalSdwnRq 0 "no" 1 "yes";
VAL_ 2650816513 BMMp_flag_InternalKL30Safe 0 "no" 1 "yes";
VAL_ 2650816513 BMMp_flag_HVILState 0 "not ok" 1 "ok";
VAL_ 2650816513 BMMp_flag_eStopLoopClosed 0 "not ok" 1 "ok";
VAL_ 2650816513 BMMp_flag_Warning 0 "no" 1 "yes";
VAL_ 2650816513 BMMp_flag_Alarm 0 "no" 1 "yes";
VAL_ 2650816513 BMMp_flag_AuxCont 0 "at least 1 aux cont open" 1 "all aux cont closed";
VAL_ 2650816513 BMMp_flag_FireRisk 0 "no" 1 "yes";
VAL_ 2650820609 BMMp_stat_IsoResMeasStatus 0 "ISO_STATE_PASSIVE" 1 "ISO_STATE_ACTIVE" 2 "ISO_STATE_ERROR" 3 "ISO_STATE_SNA";
VAL_ 2650824705 BMMp_ef_CellVoltageMax 0 "no" 1 "yes";
VAL_ 2650824705 BMMp_ef_CellVoltageMin 0 "no" 1 "yes";
VAL_ 2650824705 BMMp_ef_SysVoltageMax 0 "no" 1 "yes";
VAL_ 2650824705 BMMp_ef_SysVoltageMin 0 "no" 1 "yes";
VAL_ 2650824705 BMMp_ef_SysVoltageSum 0 "no" 1 "yes";
VAL_ 2650824705 BMMp_ef_ModVoltageSum 0 "no" 1 "yes";
VAL_ 2650824705 BMMp_ef_ModVoltageRefMax 0 "no" 1 "yes";
VAL_ 2650824705 BMMp_ef_Mod_Voltage_Ref_Min 0 "no" 1 "yes";
VAL_ 2650824705 BMMp_ef_IsoFaultBattNeg 0 "no" 1 "yes";
VAL_ 2650824705 BMMp_ef_IsoFaultBattPos 0 "no" 1 "yes";
VAL_ 2650824705 BMMp_ef_ContactorNegStuck 0 "no" 1 "yes";
VAL_ 2650824705 BMMp_ef_ContactorPosStuck 0 "no" 1 "yes";
VAL_ 2650824705 BMMp_ef_LVSupplyMax 0 "no" 1 "yes";
VAL_ 2650824705 BMMp_ef_LVSupplyMin 0 "no" 1 "yes";
VAL_ 2650824705 BMMp_ef_TerminalTempMax 0 "no" 1 "yes";
VAL_ 2650824705 BMMp_ef_TerminalTempMin 0 "no" 1 "yes";
VAL_ 2650824705 BMMp_ef_CellTempChargMax 0 "no" 1 "yes";
VAL_ 2650824705 BMMp_ef_CellTempChargMin 0 "no" 1 "yes";
VAL_ 2650824705 BMMp_ef_CellTempDischMax 0 "no" 1 "yes";
VAL_ 2650824705 BMMp_ef_CellTempDischMin 0 "no" 1 "yes";
VAL_ 2650824705 BMMp_ef_SysCurCha 0 "no" 1 "yes";
VAL_ 2650824705 BMMp_ef_SysCurDis 0 "no" 1 "yes";
VAL_ 2650824705 BMMp_ef_HVCurrLoopMax 0 "no" 1 "yes";
VAL_ 2650824705 BMMp_ef_HVCurrLoopMin 0 "no" 1 "yes";
VAL_ 2650824705 BMMp_ef_eStopCurrLoopMax 0 "no" 1 "yes";
VAL_ 2650824705 BMMp_ef_eStopCurrLoopMin 0 "no" 1 "yes";
VAL_ 2650824705 BMMp_ef_SysCurLimitCha 0 "no" 1 "yes";
VAL_ 2650824705 BMMp_ef_SysCurLimitDis 0 "no" 1 "yes";
VAL_ 2650824705 BMMp_ef_SysPrechargeFailed 0 "no" 1 "yes";
VAL_ 2650824705 BMMp_ef_BMMBattCom 0 "no" 1 "yes";
VAL_ 2650824705 BMMp_ef_SysInitTimeout 0 "no" 1 "yes";
VAL_ 2650824705 BMMp_ef_SCUConfig 0 "no" 1 "yes";
VAL_ 2650824705 BMMp_ef_DeepDischProt 0 "no" 1 "yes";
VAL_ 2650824705 BMMp_ef_WDReset 0 "no" 1 "yes";
VAL_ 2650824705 BMMp_ef_ExtCommunicationTout 0 "no" 1 "yes";
VAL_ 2650824705 BMMp_ef_NoAfterrunTest 0 "no" 1 "yes";
VAL_ 2650824705 BMMp_ef_CellVoltUnbalance 0 "no" 1 "yes";
VAL_ 2650824705 BMMp_ef_CellTempUnbalance 0 "no" 1 "yes";
VAL_ 2650824705 BMMp_ef_TerminalTempUnbalance 0 "no" 1 "yes";
VAL_ 2650824705 BMMp_ef_LTCError 0 "no" 1 "yes";
VAL_ 2650824705 BMMp_ef_AfterrunTest 0 "no" 1 "yes";
VAL_ 2650824705 BMMp_ef_CrossCheck 0 "no" 1 "yes";
VAL_ 2650824705 BMMp_ef_StuckAtTemp 0 "no" 1 "yes";
VAL_ 2650824705 BMMp_ef_StuckAtVolt 0 "no" 1 "yes";
VAL_ 2650824705 BMMp_ef_ProgProcess 0 "no" 1 "yes";
VAL_ 2650824705 BMMp_ef_RAM 0 "no" 1 "yes";
VAL_ 2650824705 BMMp_ef_ROM 0 "no" 1 "yes";
VAL_ 2650824705 BMMp_ef_FlashEEPROM 0 "no" 1 "yes";
VAL_ 2650824705 BMMp_ef_InvalidData 0 "no" 1 "yes";
VAL_ 2650824705 BMMp_ef_ContactorWrongState 0 "no" 1 "yes";
VAL_ 2650824705 BMMp_ef_CurrSens 0 "no" 1 "yes";
VAL_ 2650824705 BMMp_ef_ContDam 0 "no" 1 "yes";
VAL_ 2650824705 BMMp_ef_RefVoltErrorMax 0 "no" 1 "yes";
VAL_ 2650824705 BMMp_ef_RefVoltErrorMin 0 "no" 1 "yes";
VAL_ 2650824705 BMMp_ef_KL30SafeMax 0 "no" 1 "yes";
VAL_ 2650824705 BMMp_ef_KL30SafeMin 0 "no" 1 "yes";
VAL_ 2650824705 BMMp_ef_CPUSupplyWarning 0 "no" 1 "yes";
VAL_ 2650824705 BMMp_ef_PowerProtectionWarning 0 "no" 1 "yes";
VAL_ 2650824705 BMMp_ef_KL30SafeOff 0 "no" 1 "yes";
VAL_ 2650824705 BMMp_ef_Dew_Sensor 0 "no" 1 "yes";
VAL_ 2650824705 BMMp_ef_ContactorDropOut 0 "no" 1 "yes";
VAL_ 2650824705 BMMp_ef_BoardTemp 0 "no" 1 "yes";
VAL_ 2650824705 BMMp_ef_SCUError 0 "no" 1 "yes";
VAL_ 2650828801 BMMp_af_CellVoltageMax 0 "no" 1 "yes";
VAL_ 2650828801 BMMp_af_CellVoltageMin 0 "no" 1 "yes";
VAL_ 2650828801 BMMp_af_SysVoltageMax 0 "no" 1 "yes";
VAL_ 2650828801 BMMp_af_SysVoltageMin 0 "no" 1 "yes";
VAL_ 2650828801 BMMp_af_SysVoltageSum 0 "no" 1 "yes";
VAL_ 2650828801 BMMp_af_ModVoltageSum 0 "no" 1 "yes";
VAL_ 2650828801 BMMp_af_ModVoltageRefMax 0 "no" 1 "yes";
VAL_ 2650828801 BMMp_af_Mod_Voltage_Ref_Min 0 "no" 1 "yes";
VAL_ 2650828801 BMMp_af_IsoFaultBattNeg 0 "no" 1 "yes";
VAL_ 2650828801 BMMp_af_IsoFaultBattPos 0 "no" 1 "yes";
VAL_ 2650828801 BMMp_af_ContactorNegStuck 0 "no" 1 "yes";
VAL_ 2650828801 BMMp_af_ContactorPosStuck 0 "no" 1 "yes";
VAL_ 2650828801 BMMp_af_LVSupplyMax 0 "no" 1 "yes";
VAL_ 2650828801 BMMp_af_LVSupplyMin 0 "no" 1 "yes";
VAL_ 2650828801 BMMp_af_TerminalTempMax 0 "no" 1 "yes";
VAL_ 2650828801 BMMp_af_TerminalTempMin 0 "no" 1 "yes";
VAL_ 2650828801 BMMp_af_CellTempChargMax 0 "no" 1 "yes";
VAL_ 2650828801 BMMp_af_CellTempChargMin 0 "no" 1 "yes";
VAL_ 2650828801 BMMp_af_CellTempDischMax 0 "no" 1 "yes";
VAL_ 2650828801 BMMp_af_CellTempDischMin 0 "no" 1 "yes";
VAL_ 2650828801 BMMp_af_SysCurCha 0 "no" 1 "yes";
VAL_ 2650828801 BMMp_af_SysCurDis 0 "no" 1 "yes";
VAL_ 2650828801 BMMp_af_HVCurrLoopMax 0 "no" 1 "yes";
VAL_ 2650828801 BMMp_af_HVCurrLoopMin 0 "no" 1 "yes";
VAL_ 2650828801 BMMp_af_eStopCurrLoopMax 0 "no" 1 "yes";
VAL_ 2650828801 BMMp_af_eStopCurrLoopMin 0 "no" 1 "yes";
VAL_ 2650828801 BMMp_af_SysCurLimitCha 0 "no" 1 "yes";
VAL_ 2650828801 BMMp_af_SysCurLimitDis 0 "no" 1 "yes";
VAL_ 2650828801 BMMp_af_SysPrechargeFailed 0 "no" 1 "yes";
VAL_ 2650828801 BMMp_af_BMMBattCom 0 "no" 1 "yes";
VAL_ 2650828801 BMMp_af_SysInitTimeout 0 "no" 1 "yes";
VAL_ 2650828801 BMMp_af_SCUConfig 0 "no" 1 "yes";
VAL_ 2650828801 BMMp_af_DeepDischProt 0 "no" 1 "yes";
VAL_ 2650828801 BMMp_af_WDReset 0 "no" 1 "yes";
VAL_ 2650828801 BMMp_af_ExtCommunicationTout 0 "no" 1 "yes";
VAL_ 2650828801 BMMp_af_NoAfterrunTest 0 "no" 1 "yes";
VAL_ 2650828801 BMMp_af_CellVoltUnbalance 0 "no" 1 "yes";
VAL_ 2650828801 BMMp_af_CellTempUnbalance 0 "no" 1 "yes";
VAL_ 2650828801 BMMp_af_TerminalTempUnbalance 0 "no" 1 "yes";
VAL_ 2650828801 BMMp_af_LTCError 0 "no" 1 "yes";
VAL_ 2650828801 BMMp_af_AfterrunTest 0 "no" 1 "yes";
VAL_ 2650828801 BMMp_af_CrossCheck 0 "no" 1 "yes";
VAL_ 2650828801 BMMp_af_StuckAtTemp 0 "no" 1 "yes";
VAL_ 2650828801 BMMp_af_StuckAtVolt 0 "no" 1 "yes";
VAL_ 2650828801 BMMp_af_ProgProcess 0 "no" 1 "yes";
VAL_ 2650828801 BMMp_af_RAM 0 "no" 1 "yes";
VAL_ 2650828801 BMMp_af_ROM 0 "no" 1 "yes";
VAL_ 2650828801 BMMp_af_FlashEEPROM 0 "no" 1 "yes";
VAL_ 2650828801 BMMp_af_InvalidData 0 "no" 1 "yes";
VAL_ 2650828801 BMMp_af_ContactorWrongState 0 "no" 1 "yes";
VAL_ 2650828801 BMMp_af_CurrSens 0 "no" 1 "yes";
VAL_ 2650828801 BMMp_af_ContDam 0 "no" 1 "yes";
VAL_ 2650828801 BMMp_af_RefVoltErrorMax 0 "no" 1 "yes";
VAL_ 2650828801 BMMp_af_RefVoltErrorMin 0 "no" 1 "yes";
VAL_ 2650828801 BMMp_af_KL30SafeMax 0 "no" 1 "yes";
VAL_ 2650828801 BMMp_af_KL30SafeMin 0 "no" 1 "yes";
VAL_ 2650828801 BMMp_af_CPUSupplyWarning 0 "no" 1 "yes";
VAL_ 2650828801 BMMp_af_PowerProtectionWarning 0 "no" 1 "yes";
VAL_ 2650828801 BMMp_af_KL30SafeOff 0 "no" 1 "yes";
VAL_ 2650828801 BMMp_af_Dew_Sensor 0 "no" 1 "yes";
VAL_ 2650828801 BMMp_af_ContactorDropOut 0 "no" 1 "yes";
VAL_ 2650828801 BMMp_af_BoardTemp 0 "no" 1 "yes";
VAL_ 2650828801 BMMp_af_SCUError 0 "no" 1 "yes";
VAL_ 2650832897 BMMp_wf_CellVoltageMax 0 "no" 1 "yes";
VAL_ 2650832897 BMMp_wf_CellVoltageMin 0 "no" 1 "yes";
VAL_ 2650832897 BMMp_wf_SysVoltageMax 0 "no" 1 "yes";
VAL_ 2650832897 BMMp_wf_SysVoltageMin 0 "no" 1 "yes";
VAL_ 2650832897 BMMp_wf_SysVoltageSum 0 "no" 1 "yes";
VAL_ 2650832897 BMMp_wf_ModVoltageSum 0 "no" 1 "yes";
VAL_ 2650832897 BMMp_wf_ModVoltageRefMax 0 "no" 1 "yes";
VAL_ 2650832897 BMMp_wf_Mod_Voltage_Ref_Min 0 "no" 1 "yes";
VAL_ 2650832897 BMMp_wf_IsoFaultBattNeg 0 "no" 1 "yes";
VAL_ 2650832897 BMMp_wf_IsoFaultBattPos 0 "no" 1 "yes";
VAL_ 2650832897 BMMp_wf_ContactorNegStuck 0 "no" 1 "yes";
VAL_ 2650832897 BMMp_wf_ContactorPosStuck 0 "no" 1 "yes";
VAL_ 2650832897 BMMp_wf_LVSupplyMax 0 "no" 1 "yes";
VAL_ 2650832897 BMMp_wf_LVSupplyMin 0 "no" 1 "yes";
VAL_ 2650832897 BMMp_wf_TerminalTempMax 0 "no" 1 "yes";
VAL_ 2650832897 BMMp_wf_TerminalTempMin 0 "no" 1 "yes";
VAL_ 2650832897 BMMp_wf_CellTempChargMax 0 "no" 1 "yes";
VAL_ 2650832897 BMMp_wf_CellTempChargMin 0 "no" 1 "yes";
VAL_ 2650832897 BMMp_wf_CellTempDischMax 0 "no" 1 "yes";
VAL_ 2650832897 BMMp_wf_CellTempDischMin 0 "no" 1 "yes";
VAL_ 2650832897 BMMp_wf_SysCurCha 0 "no" 1 "yes";
VAL_ 2650832897 BMMp_wf_SysCurDis 0 "no" 1 "yes";
VAL_ 2650832897 BMMp_wf_HVCurrLoopMax 0 "no" 1 "yes";
VAL_ 2650832897 BMMp_wf_HVCurrLoopMin 0 "no" 1 "yes";
VAL_ 2650832897 BMMp_wf_eStopCurrLoopMax 0 "no" 1 "yes";
VAL_ 2650832897 BMMp_wf_eStopCurrLoopMin 0 "no" 1 "yes";
VAL_ 2650832897 BMMp_wf_SysCurLimitCha 0 "no" 1 "yes";
VAL_ 2650832897 BMMp_wf_SysCurLimitDis 0 "no" 1 "yes";
VAL_ 2650832897 BMMp_wf_SysPrechargeFailed 0 "no" 1 "yes";
VAL_ 2650832897 BMMp_wf_BMMBattCom 0 "no" 1 "yes";
VAL_ 2650832897 BMMp_wf_SysInitTimeout 0 "no" 1 "yes";
VAL_ 2650832897 BMMp_wf_SCUConfig 0 "no" 1 "yes";
VAL_ 2650832897 BMMp_wf_DeepDischProt 0 "no" 1 "yes";
VAL_ 2650832897 BMMp_wf_WDReset 0 "no" 1 "yes";
VAL_ 2650832897 BMMp_wf_ExtCommunicationTout 0 "no" 1 "yes";
VAL_ 2650832897 BMMp_wf_NoAfterrunTest 0 "no" 1 "yes";
VAL_ 2650832897 BMMp_wf_CellVoltUnbalance 0 "no" 1 "yes";
VAL_ 2650832897 BMMp_wf_CellTempUnbalance 0 "no" 1 "yes";
VAL_ 2650832897 BMMp_wf_TerminalTempUnbalance 0 "no" 1 "yes";
VAL_ 2650832897 BMMp_wf_LTCError 0 "no" 1 "yes";
VAL_ 2650832897 BMMp_wf_AfterrunTest 0 "no" 1 "yes";
VAL_ 2650832897 BMMp_wf_CrossCheck 0 "no" 1 "yes";
VAL_ 2650832897 BMMp_wf_StuckAtTemp 0 "no" 1 "yes";
VAL_ 2650832897 BMMp_wf_StuckAtVolt 0 "no" 1 "yes";
VAL_ 2650832897 BMMp_wf_ProgProcess 0 "no" 1 "yes";
VAL_ 2650832897 BMMp_wf_RAM 0 "no" 1 "yes";
VAL_ 2650832897 BMMp_wf_ROM 0 "no" 1 "yes";
VAL_ 2650832897 BMMp_wf_FlashEEPROM 0 "no" 1 "yes";
VAL_ 2650832897 BMMp_wf_InvalidData 0 "no" 1 "yes";
VAL_ 2650832897 BMMp_wf_ContactorWrongState 0 "no" 1 "yes";
VAL_ 2650832897 BMMp_wf_CurrSens 0 "no" 1 "yes";
VAL_ 2650832897 BMMp_wf_ContDam 0 "no" 1 "yes";
VAL_ 2650832897 BMMp_wf_RefVoltErrorMax 0 "no" 1 "yes";
VAL_ 2650832897 BMMp_wf_RefVoltErrorMin 0 "no" 1 "yes";
VAL_ 2650832897 BMMp_wf_KL30SafeMax 0 "no" 1 "yes";
VAL_ 2650832897 BMMp_wf_KL30SafeMin 0 "no" 1 "yes";
VAL_ 2650832897 BMMp_wf_CPUSupplyWarning 0 "no" 1 "yes";
VAL_ 2650832897 BMMp_wf_PowerProtectionWarning 0 "no" 1 "yes";
VAL_ 2650832897 BMMp_wf_KL30SafeOff 0 "no" 1 "yes";
VAL_ 2650832897 BMMp_wf_Dew_Sensor 0 "no" 1 "yes";
VAL_ 2650832897 BMMp_wf_ContactorDropOut 0 "no" 1 "yes";
VAL_ 2650832897 BMMp_wf_BoardTemp 0 "no" 1 "yes";
VAL_ 2650832897 BMMp_wf_SCUError 0 "no" 1 "yes";
VAL_ 2650890241 BMMp_wf_FanError 0 "no" 1 "yes";

SIG_VALTYPE_ 2651182081 Param2 : 1;
SIG_VALTYPE_ 2651186177 Simu_Value : 1;
